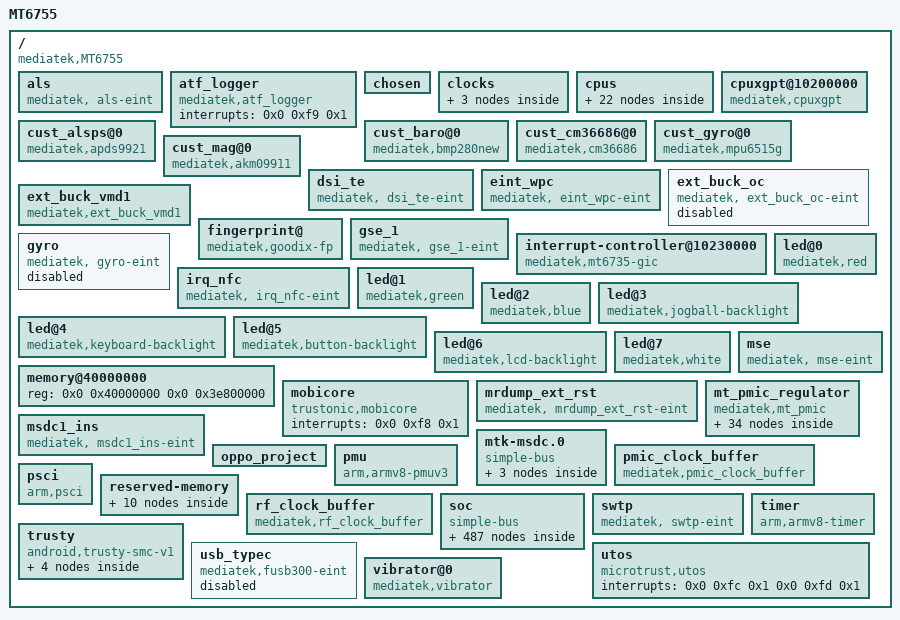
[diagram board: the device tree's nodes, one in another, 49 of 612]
/dts-v1/;

/ {
	#address-cells = <0x2>;
	#size-cells = <0x2>;
	compatible = "mediatek,MT6755";
	interrupt-parent = <0x1>;
	model = "MT6755";

	als {
		compatible = "mediatek, als-eint";
		debounce = <0x6 0x0>;
		interrupt-parent = <0x1c>;
		interrupts = <0x6 0x2>;
		status = "okay";
	};

	atf_logger {
		compatible = "mediatek,atf_logger";
		interrupts = <0x0 0xf9 0x1>;
	};

	chosen {
		atag,videolfb-fb_base_h = <0x0>;
		atag,videolfb-fb_base_l = <0x7e800000>;
		atag,videolfb-fps = <0x1770>;
		atag,videolfb-islcm_inited = <0x0>;
		atag,videolfb-islcmfound = <0x1>;
		atag,videolfb-lcmname = "nt35695_fhd_dsi_cmd_truly_nt50358_drv";
		atag,videolfb-vramSize = <0x1800000>;
		bootargs = "console=tty0 console=ttyMT0,921600n1 root=/dev/ram initrd=0x44000000,0x4B434E loglevel=8";
	};

	clocks {

		clk26m {
			#clock-cells = <0x0>;
			clock-frequency = <0x18cba80>;
			compatible = "fixed-clock";
			linux,phandle = <0x41>;
			phandle = <0x41>;
		};

		clk32k {
			#clock-cells = <0x0>;
			clock-frequency = <0x7d00>;
			compatible = "fixed-clock";
			linux,phandle = <0x21>;
			phandle = <0x21>;
		};

		clk_null {
			#clock-cells = <0x0>;
			clock-frequency = <0x0>;
			compatible = "fixed-clock";
		};
	};

	cpus {
		#address-cells = <0x1>;
		#size-cells = <0x0>;

		cpu-map {

			cluster0 {

				core0 {
					cpu = <0x14>;
				};

				core1 {
					cpu = <0x15>;
				};

				core2 {
					cpu = <0x16>;
				};

				core3 {
					cpu = <0x17>;
				};
			};

			cluster1 {

				core0 {
					cpu = <0x18>;
				};

				core1 {
					cpu = <0x19>;
				};

				core2 {
					cpu = <0x1a>;
				};

				core3 {
					cpu = <0x1b>;
				};
			};
		};

		cpu@000 {
			clock-frequency = <0x44300e00>;
			compatible = "arm,cortex-a53";
			cpu-idle-states = <0x12 0x12 0x12 0x13 0x13 0x13>;
			cpu-release-addr = <0x0 0x40000200>;
			device_type = "cpu";
			enable-method = "mt-boot";
			linux,phandle = <0x14>;
			phandle = <0x14>;
			reg = <0x0>;
		};

		cpu@001 {
			clock-frequency = <0x44300e00>;
			compatible = "arm,cortex-a53";
			cpu-idle-states = <0x12 0x12 0x12 0x13 0x13 0x13>;
			cpu-release-addr = <0x0 0x40000200>;
			device_type = "cpu";
			enable-method = "mt-boot";
			linux,phandle = <0x15>;
			phandle = <0x15>;
			reg = <0x1>;
		};

		cpu@002 {
			clock-frequency = <0x44300e00>;
			compatible = "arm,cortex-a53";
			cpu-idle-states = <0x12 0x12 0x12 0x13 0x13 0x13>;
			cpu-release-addr = <0x0 0x40000200>;
			device_type = "cpu";
			enable-method = "mt-boot";
			linux,phandle = <0x16>;
			phandle = <0x16>;
			reg = <0x2>;
		};

		cpu@003 {
			clock-frequency = <0x44300e00>;
			compatible = "arm,cortex-a53";
			cpu-idle-states = <0x12 0x12 0x12 0x13 0x13 0x13>;
			cpu-release-addr = <0x0 0x40000200>;
			device_type = "cpu";
			enable-method = "mt-boot";
			linux,phandle = <0x17>;
			phandle = <0x17>;
			reg = <0x3>;
		};

		cpu@100 {
			clock-frequency = <0x743aa380>;
			compatible = "arm,cortex-a53";
			cpu-idle-states = <0x12 0x12 0x12 0x13 0x13 0x13>;
			cpu-release-addr = <0x0 0x40000200>;
			device_type = "cpu";
			enable-method = "mt-boot";
			linux,phandle = <0x18>;
			phandle = <0x18>;
			reg = <0x100>;
		};

		cpu@101 {
			clock-frequency = <0x743aa380>;
			compatible = "arm,cortex-a53";
			cpu-idle-states = <0x12 0x12 0x12 0x13 0x13 0x13>;
			cpu-release-addr = <0x0 0x40000200>;
			device_type = "cpu";
			enable-method = "mt-boot";
			linux,phandle = <0x19>;
			phandle = <0x19>;
			reg = <0x101>;
		};

		cpu@102 {
			clock-frequency = <0x743aa380>;
			compatible = "arm,cortex-a53";
			cpu-idle-states = <0x12 0x12 0x12 0x13 0x13 0x13>;
			cpu-release-addr = <0x0 0x40000200>;
			device_type = "cpu";
			enable-method = "mt-boot";
			linux,phandle = <0x1a>;
			phandle = <0x1a>;
			reg = <0x102>;
		};

		cpu@103 {
			clock-frequency = <0x743aa380>;
			compatible = "arm,cortex-a53";
			cpu-idle-states = <0x12 0x12 0x12 0x13 0x13 0x13>;
			cpu-release-addr = <0x0 0x40000200>;
			device_type = "cpu";
			enable-method = "mt-boot";
			linux,phandle = <0x1b>;
			phandle = <0x1b>;
			reg = <0x103>;
		};

		idle-states {
			entry-method = "arm,psci";

			cluster-sleep-0 {
				arm,psci-suspend-param = <0x1010000>;
				compatible = "arm,idle-state";
				entry-latency-us = <0x320>;
				exit-latency-us = <0x3e8>;
				linux,phandle = <0x12>;
				min-residency-us = <0x7d0>;
				phandle = <0x12>;
			};

			cpu-sleep-0-0 {
				arm,psci-suspend-param = <0x10000>;
				compatible = "arm,idle-state";
				entry-latency-us = <0x258>;
				exit-latency-us = <0x258>;
				linux,phandle = <0x13>;
				min-residency-us = <0x4b0>;
				phandle = <0x13>;
			};
		};
	};

	cpuxgpt@10200000 {
		compatible = "mediatek,cpuxgpt";
		interrupts = <0x0 0x40 0x4 0x0 0x41 0x4 0x0 0x42 0x4 0x0 0x43 0x4 0x0 0x44 0x4 0x0 0x45 0x4 0x0 0x46 0x4 0x0 0x47 0x4>;
		reg = <0x0 0x10200000 0x0 0x1000>;
	};

	cust_alsps@0 {
		als_gain1 = <0x2>;
		als_gain2 = <0x3>;
		als_level = <0x0 0x101 0x27d 0x403 0x8f9 0x15d4 0x1a4a 0x2c25 0x4fe1 0x64a8 0x7992 0xb1f0 0xe251 0xe251 0xe251>;
		als_value = <0x0 0x84 0x130 0x1f6 0x3ec 0x7d3 0xbbe 0x138e 0x1f44 0x2710 0x2ee0 0x3e80 0x4e20 0x4e20 0x4e20 0x4e20>;
		compatible = "mediatek,apds9921";
		eint_gpio = <0x6>;
		i2c_addr = <0x53 0x0 0x0 0x0>;
		i2c_num = <0x1>;
		is_batch_supported_als = <0x1>;
		is_batch_supported_ps = <0x1>;
		polling_mode_als = <0x1>;
		polling_mode_ps = <0x0>;
		power_id = <0xffff>;
		power_vol = <0x0>;
		ps_threshold_high = <0x190>;
		ps_threshold_low = <0x15e>;
		sec_para_supported = <0x1>;
	};

	cust_baro@0 {
		compatible = "mediatek,bmp280new";
		direction = <0x0>;
		firlen = <0x20>;
		i2c_num = <0x1>;
		is_batch_supported = <0x0>;
		power_id = <0xffff>;
		power_vol = <0x0>;
	};

	cust_cm36686@0 {
		als_gain1 = <0x2>;
		als_gain2 = <0x3>;
		als_level = <0x0 0x101 0x27d 0x403 0x8f9 0x15d4 0x1a4a 0x2c25 0x4fe1 0x64a8 0x7992 0xb1f0 0xe251 0xe251 0xe251>;
		als_value = <0x0 0x84 0x130 0x1f6 0x3ec 0x7d3 0xbbe 0x138e 0x1f44 0x2710 0x2ee0 0x3e80 0x4e20 0x4e20 0x4e20 0x4e20>;
		compatible = "mediatek,cm36686";
		eint_gpio = <0x6>;
		i2c_addr = <0x60 0x0 0x0 0x0>;
		i2c_num = <0x1>;
		is_batch_supported_als = <0x1>;
		is_batch_supported_ps = <0x1>;
		polling_mode_als = <0x1>;
		polling_mode_ps = <0x0>;
		power_id = <0xffff>;
		power_vol = <0x0>;
		ps_threshold_high = <0x190>;
		ps_threshold_low = <0x15e>;
		sec_para_supported = <0x1>;
	};

	cust_gyro@0 {
		compatible = "mediatek,mpu6515g";
		direction = <0x6>;
		firlen = <0x0>;
		i2c_num = <0x1>;
		is_batch_supported = <0x0>;
		power_id = <0xffff>;
		power_vol = <0x0>;
	};

	cust_mag@0 {
		compatible = "mediatek,akm09911";
		direction = <0x3>;
		i2c_addr = <0xc 0x0 0x0 0x0>;
		i2c_num = <0x1>;
		power_id = <0xffff>;
		power_vol = <0x0>;
	};

	dsi_te {
		compatible = "mediatek, dsi_te-eint";
		debounce = <0x2c 0x0>;
		interrupt-parent = <0x1c>;
		interrupts = <0x2c 0x1>;
		status = "okay";
	};

	eint_wpc {
		compatible = "mediatek, eint_wpc-eint";
		debounce = <0x2a 0x0>;
		interrupt-parent = <0x1c>;
		interrupts = <0x2a 0x1>;
		status = "okay";
	};

	ext_buck_oc {
		compatible = "mediatek, ext_buck_oc-eint";
		status = "disabled";
	};

	ext_buck_vmd1 {
		compatible = "mediatek,ext_buck_vmd1";
		pinctrl-0 = <0x8e>;
		pinctrl-1 = <0x8f>;
		pinctrl-2 = <0x90>;
		pinctrl-names = "default", "vmd1_sel_low", "vmd1_sel_high";
	};

	fingerprint@ {
		compatible = "mediatek,goodix-fp";
	};

	gse_1 {
		compatible = "mediatek, gse_1-eint";
		debounce = <0x4 0x0>;
		interrupt-parent = <0x1c>;
		interrupts = <0x4 0x2>;
		status = "okay";
	};

	gyro {
		compatible = "mediatek, gyro-eint";
		status = "disabled";
	};

	interrupt-controller@10230000 {
		#address-cells = <0x0>;
		#interrupt-cells = <0x3>;
		compatible = "mediatek,mt6735-gic";
		interrupt-controller;
		linux,phandle = <0x1>;
		phandle = <0x1>;
		reg = <0x0 0x10231000 0x0 0x1000 0x0 0x10232000 0x0 0x1000 0x0 0x10200620 0x0 0x1000>;
	};

	irq_nfc {
		compatible = "mediatek, irq_nfc-eint";
		debounce = <0x1a 0x0>;
		interrupt-parent = <0x1c>;
		interrupts = <0x1a 0x4>;
		status = "okay";
	};

	led@0 {
		compatible = "mediatek,red";
		data = <0x1>;
		led_mode = <0x0>;
		pwm_config = <0x0 0x0 0x0 0x0 0x0>;
	};

	led@1 {
		compatible = "mediatek,green";
		data = <0x1>;
		led_mode = <0x0>;
		pwm_config = <0x0 0x0 0x0 0x0 0x0>;
	};

	led@2 {
		compatible = "mediatek,blue";
		data = <0x1>;
		led_mode = <0x0>;
		pwm_config = <0x0 0x0 0x0 0x0 0x0>;
	};

	led@3 {
		compatible = "mediatek,jogball-backlight";
		data = <0x1>;
		led_mode = <0x0>;
		pwm_config = <0x0 0x0 0x0 0x0 0x0>;
	};

	led@4 {
		compatible = "mediatek,keyboard-backlight";
		data = <0x1>;
		led_mode = <0x0>;
		pwm_config = <0x0 0x0 0x0 0x0 0x0>;
	};

	led@5 {
		compatible = "mediatek,button-backlight";
		data = <0x1>;
		led_mode = <0x0>;
		pwm_config = <0x0 0x0 0x0 0x0 0x0>;
	};

	led@6 {
		compatible = "mediatek,lcd-backlight";
		data = <0x1>;
		led_mode = <0x4>;
		pwm_config = <0x0 0x0 0x0 0x0 0x0>;
	};

	led@7 {
		compatible = "mediatek,white";
		data = <0x1>;
		led_mode = <0x3>;
		pwm_config = <0x0 0x0 0x0 0x0 0x0>;
	};

	memory@40000000 {
		device_type = "memory";
		reg = <0x0 0x40000000 0x0 0x3e800000>;
	};

	mobicore {
		compatible = "trustonic,mobicore";
		interrupts = <0x0 0xf8 0x1>;
	};

	mrdump_ext_rst {
		compatible = "mediatek, mrdump_ext_rst-eint";
		debounce = <0x7 0x7d000>;
		interrupt-parent = <0x1c>;
		interrupts = <0x7 0x8>;
		status = "okay";
	};

	msdc1_ins {
		compatible = "mediatek, msdc1_ins-eint";
		debounce = <0x3 0x3e8>;
		interrupt-parent = <0x1c>;
		interrupts = <0x3 0x8>;
		status = "okay";
	};

	mse {
		compatible = "mediatek, mse-eint";
		debounce = <0x5 0x0>;
		interrupt-parent = <0x1c>;
		interrupts = <0x5 0x4>;
		status = "okay";
	};

	mt_pmic_regulator {
		compatible = "mediatek,mt_pmic";

		buck_regulators {
			compatible = "mediatek,mt_pmic_buck_regulators";

			buck_vcore {
				regulator-boot-on;
				regulator-enable-ramp-delay = <0x1e>;
				regulator-max-microvolt = <0x154456>;
				regulator-min-microvolt = <0x927c0>;
				regulator-name = "vcore";
				regulator-ramp-delay = <0x186a>;
			};

			buck_vcore2 {
				regulator-boot-on;
				regulator-enable-ramp-delay = <0x1e>;
				regulator-max-microvolt = <0x154456>;
				regulator-min-microvolt = <0x927c0>;
				regulator-name = "vcore2";
				regulator-ramp-delay = <0x186a>;
			};

			buck_vproc {
				regulator-always-on;
				regulator-boot-on;
				regulator-enable-ramp-delay = <0x1e>;
				regulator-max-microvolt = <0x154456>;
				regulator-min-microvolt = <0x927c0>;
				regulator-name = "vproc";
				regulator-ramp-delay = <0x186a>;
			};

			buck_vs1 {
				regulator-always-on;
				regulator-boot-on;
				regulator-enable-ramp-delay = <0x1e>;
				regulator-max-microvolt = <0x154456>;
				regulator-min-microvolt = <0x927c0>;
				regulator-name = "vs1";
				regulator-ramp-delay = <0x186a>;
			};
		};

		ldo_regulators {
			compatible = "mediatek,mt_pmic_ldo_regulators";

			ldo_vaud28 {
				regulator-boot-on;
				regulator-enable-ramp-delay = <0xf0>;
				regulator-max-microvolt = <0x2ab980>;
				regulator-min-microvolt = <0x1b7740>;
				regulator-name = "vaud28";
			};

			ldo_vaux18 {
				regulator-boot-on;
				regulator-enable-ramp-delay = <0xf0>;
				regulator-max-microvolt = <0x2ab980>;
				regulator-min-microvolt = <0x1b7740>;
				regulator-name = "vaux18";
			};

			ldo_vcama {
				linux,phandle = <0x51>;
				phandle = <0x51>;
				regulator-default-on = <0x0>;
				regulator-enable-ramp-delay = <0xf0>;
				regulator-max-microvolt = <0x2ab980>;
				regulator-min-microvolt = <0x16e360>;
				regulator-name = "vcama";
				status = "okay";
			};

			ldo_vcamd {
				linux,phandle = <0x52>;
				phandle = <0x52>;
				regulator-default-on = <0x0>;
				regulator-enable-ramp-delay = <0xf0>;
				regulator-max-microvolt = <0x1b7740>;
				regulator-min-microvolt = <0xdbba0>;
				regulator-name = "vcamd";
				status = "okay";
			};

			ldo_vcamio {
				linux,phandle = <0x53>;
				phandle = <0x53>;
				regulator-default-on = <0x0>;
				regulator-enable-ramp-delay = <0xf0>;
				regulator-max-microvolt = <0x1b7740>;
				regulator-min-microvolt = <0x124f80>;
				regulator-name = "vcamio";
				status = "okay";
			};

			ldo_vcn18 {
				regulator-enable-ramp-delay = <0xf0>;
				regulator-max-microvolt = <0x1b7740>;
				regulator-min-microvolt = <0x1b7740>;
				regulator-name = "vcn18";
			};

			ldo_vcn28 {
				regulator-enable-ramp-delay = <0xf0>;
				regulator-max-microvolt = <0x2ab980>;
				regulator-min-microvolt = <0x1b7740>;
				regulator-name = "vcn28";
			};

			ldo_vcn33_bt {
				regulator-enable-ramp-delay = <0xf0>;
				regulator-max-microvolt = <0x36ee80>;
				regulator-min-microvolt = <0x325aa0>;
				regulator-name = "vcn33_bt";
			};

			ldo_vcn33_wifi {
				regulator-enable-ramp-delay = <0xf0>;
				regulator-max-microvolt = <0x36ee80>;
				regulator-min-microvolt = <0x325aa0>;
				regulator-name = "vcn33_wifi";
			};

			ldo_vdram {
				linux,phandle = <0x9c>;
				phandle = <0x9c>;
				regulator-boot-on;
				regulator-enable-ramp-delay = <0xf0>;
				regulator-max-microvolt = <0x177fa0>;
				regulator-min-microvolt = <0x12ebc0>;
				regulator-name = "vdram";
			};

			ldo_vemc {
				linux,phandle = <0x5>;
				phandle = <0x5>;
				regulator-boot-on;
				regulator-enable-ramp-delay = <0xf0>;
				regulator-max-microvolt = <0x325aa0>;
				regulator-min-microvolt = <0x2c4020>;
				regulator-name = "vemc";
			};

			ldo_vibr {
				linux,phandle = <0x96>;
				phandle = <0x96>;
				regulator-default-on = <0x0>;
				regulator-enable-ramp-delay = <0x28>;
				regulator-max-microvolt = <0x325aa0>;
				regulator-min-microvolt = <0x124f80>;
				regulator-name = "vibr";
				status = "okay";
			};

			ldo_vio18 {
				linux,phandle = <0x98>;
				phandle = <0x98>;
				regulator-boot-on;
				regulator-enable-ramp-delay = <0xf0>;
				regulator-max-microvolt = <0x1b7740>;
				regulator-min-microvolt = <0x1b7740>;
				regulator-name = "vio18";
			};

			ldo_vio28 {
				linux,phandle = <0x95>;
				phandle = <0x95>;
				regulator-boot-on;
				regulator-enable-ramp-delay = <0xf0>;
				regulator-max-microvolt = <0x2ab980>;
				regulator-min-microvolt = <0x2ab980>;
				regulator-name = "vio28";
			};

			ldo_vldo28 {
				linux,phandle = <0x54>;
				phandle = <0x54>;
				regulator-default-on = <0x0>;
				regulator-enable-ramp-delay = <0xf0>;
				regulator-max-microvolt = <0x325aa0>;
				regulator-min-microvolt = <0x124f80>;
				regulator-name = "vldo28";
				status = "okay";
			};

			ldo_vldo28_1 {
				regulator-enable-ramp-delay = <0xf0>;
				regulator-max-microvolt = <0x325aa0>;
				regulator-min-microvolt = <0x124f80>;
				regulator-name = "vldo28_1";
			};

			ldo_vmc {
				linux,phandle = <0xd>;
				phandle = <0xd>;
				regulator-enable-ramp-delay = <0xf0>;
				regulator-max-microvolt = <0x325aa0>;
				regulator-min-microvolt = <0x124f80>;
				regulator-name = "vmc";
			};

			ldo_vmch {
				linux,phandle = <0xc>;
				phandle = <0xc>;
				regulator-enable-ramp-delay = <0x28>;
				regulator-max-microvolt = <0x325aa0>;
				regulator-min-microvolt = <0x2c4020>;
				regulator-name = "vmch";
			};

			ldo_vrf12 {
				linux,phandle = <0x9b>;
				phandle = <0x9b>;
				regulator-enable-ramp-delay = <0xc8>;
				regulator-max-microvolt = <0x1b7740>;
				regulator-min-microvolt = <0xdbba0>;
				regulator-name = "vrf12";
			};

			ldo_vrf18 {
				linux,phandle = <0x97>;
				phandle = <0x97>;
				regulator-enable-ramp-delay = <0xc8>;
				regulator-max-microvolt = <0x1b7740>;
				regulator-min-microvolt = <0x1b7740>;
				regulator-name = "vrf18";
			};

			ldo_vsim1 {
				linux,phandle = <0x93>;
				phandle = <0x93>;
				regulator-default-on = <0x0>;
				regulator-enable-ramp-delay = <0xf0>;
				regulator-max-microvolt = <0x2f4d60>;
				regulator-min-microvolt = <0x19f0a0>;
				regulator-name = "vsim1";
				status = "okay";
			};

			ldo_vsim2 {
				linux,phandle = <0x94>;
				phandle = <0x94>;
				regulator-default-on = <0x0>;
				regulator-enable-ramp-delay = <0xf0>;
				regulator-max-microvolt = <0x2f4d60>;
				regulator-min-microvolt = <0x19f0a0>;
				regulator-name = "vsim2";
				status = "okay";
			};

			ldo_vsram_proc {
				linux,phandle = <0x99>;
				phandle = <0x99>;
				regulator-boot-on;
				regulator-enable-ramp-delay = <0xc8>;
				regulator-max-microvolt = <0x154456>;
				regulator-min-microvolt = <0x927c0>;
				regulator-name = "vsram_proc";
				regulator-ramp-delay = <0x186a>;
			};

			ldo_vtcxo24 {
				linux,phandle = <0x91>;
				phandle = <0x91>;
				regulator-boot-on;
				regulator-enable-ramp-delay = <0x64>;
				regulator-max-microvolt = <0x2ab980>;
				regulator-min-microvolt = <0x1b7740>;
				regulator-name = "vtcxo24";
			};

			ldo_vtcxo28 {
				linux,phandle = <0x92>;
				phandle = <0x92>;
				regulator-enable-ramp-delay = <0x64>;
				regulator-max-microvolt = <0x2ab980>;
				regulator-min-microvolt = <0x1b7740>;
				regulator-name = "vtcxo28";
			};

			ldo_vusb33 {
				regulator-boot-on;
				regulator-enable-ramp-delay = <0xf0>;
				regulator-max-microvolt = <0x325aa0>;
				regulator-min-microvolt = <0x325aa0>;
				regulator-name = "vusb33";
			};

			ldo_vxo22 {
				linux,phandle = <0x9a>;
				phandle = <0x9a>;
				regulator-boot-on;
				regulator-enable-ramp-delay = <0x64>;
				regulator-max-microvolt = <0x2ab980>;
				regulator-min-microvolt = <0x1b7740>;
				regulator-name = "vxo22";
			};
		};

		regulators_supply {
			compatible = "mediatek,mt_pmic_regulator_supply";
			vdram-supply = <0x9c>;
			vemc-supply = <0x5>;
			vibr-supply = <0x96>;
			vio18-supply = <0x98>;
			vio28-supply = <0x95>;
			vmc-supply = <0xd>;
			vmch-supply = <0xc>;
			vrf12-supply = <0x9b>;
			vrf18-supply = <0x97>;
			vsim1-supply = <0x93>;
			vsim2-supply = <0x94>;
			vsram_proc-supply = <0x99>;
			vtcxo24-supply = <0x91>;
			vtcxo28-supply = <0x92>;
			vxo22-supply = <0x9a>;
		};
	};

	mtk-msdc.0 {
		#address-cells = <0x1>;
		#size-cells = <0x1>;
		compatible = "simple-bus";
		ranges = <0x0 0x0 0x0 0xffffffff>;

		msdc0@11230000 {
			bootable;
			bus-width = <0x8>;
			cap-mmc-highspeed;
			clk_src = [01];
			clock-names = "MSDC0-CLOCK";
			clocks = <0x2 0x1e>;
			compatible = "mediatek,mt6755-mmc";
			host_function = [00];
			interrupts = <0x0 0x4f 0x8>;
			max-frequency = <0xbebc200>;
			mmc-hs200-1_8v;
			mmc-hs400-1_8v;
			msdc-sys-suspend;
			non-removable;
			pinctl = <0x3>;
			reg = <0x11230000 0x10000>;
			register_setting = <0x4>;
			status = "okay";
			vmmc-supply = <0x5>;
		};

		msdc1@11240000 {
			bus-width = <0x4>;
			cap-sd-highspeed;
			cd-gpios = <0xb 0x3 0x0>;
			cd_level = [01];
			clk_src = [07];
			clock-names = "MSDC1-CLOCK";
			clocks = <0x2 0x20>;
			compatible = "mediatek,mt6755-mmc";
			host_function = [01];
			interrupts = <0x0 0x50 0x8>;
			max-frequency = <0xbebc200>;
			msdc-sys-suspend;
			pinctl = <0x6>;
			pinctl_ddr50 = <0x9>;
			pinctl_sdr104 = <0x7>;
			pinctl_sdr50 = <0x8>;
			pinctrl-0 = <0xe>;
			pinctrl-1 = <0xf>;
			pinctrl-names = "msdc1_on", "msdc1_off";
			reg = <0x11240000 0x10000>;
			register_setting = <0xa>;
			sd-uhs-sdr104;
			sd-uhs-sdr12;
			sd-uhs-sdr25;
			sd-uhs-sdr50;
			status = "okay";
			vmmc-supply = <0xc>;
			vqmmc-supply = <0xd>;
		};

		msdc2@11250000 {
			bus-width = <0x4>;
			cap-sd-highspeed;
			clk_src = [07];
			clock-names = "MSDC2-CLOCK";
			clocks = <0x2 0x21>;
			compatible = "mediatek,mt6755-mmc";
			host_function = [02];
			interrupts = <0x0 0x51 0x8>;
			keep-power-in-suspend;
			max-frequency = <0xbebc200>;
			non-removable;
			pinctl = <0x10>;
			reg = <0x11250000 0x10000>;
			register_setting = <0x11>;
			sd-uhs-ddr50;
			sd-uhs-sdr104;
			sd-uhs-sdr12;
			sd-uhs-sdr25;
			sd-uhs-sdr50;
			status = "disable";
		};
	};

	oppo_project {
		nModem = <0x0>;
		nOperator = <0x0>;
		nPCBVersion = <0x0>;
		nProject = <0x0>;
	};

	pmic_clock_buffer {
		compatible = "mediatek,pmic_clock_buffer";
		mediatek,clkbuf-config = <0x2 0x1 0x1 0x2>;
		mediatek,clkbuf-driving-current = <0x2 0x2 0x2 0x2>;
		mediatek,clkbuf-quantity = <0x4>;
		status = "okay";
	};

	pmu {
		compatible = "arm,armv8-pmuv3";
		interrupts = <0x0 0x8 0x8 0x0 0x9 0x8 0x0 0xa 0x8 0x0 0xb 0x8 0x0 0xc 0x8 0x0 0xd 0x8 0x0 0xe 0x8 0x0 0xf 0x8>;
	};

	psci {
		affinity_info = <0x84000004>;
		compatible = "arm,psci";
		cpu_off = <0x84000002>;
		cpu_on = <0x84000003>;
		cpu_suspend = <0x84000001>;
		method = "smc";
	};

	reserved-memory {
		#address-cells = <0x2>;
		#size-cells = <0x2>;
		ranges;

		atf-reserved-memory@44600000 {
			compatible = "mediatek,mt6755-atf-reserved-memory";
			no-map;
			reg = <0x0 0x44600000 0x0 0x40000>;
		};

		consys-reserve-memory {
			alignment = <0x0 0x200000>;
			alloc-ranges = <0x0 0x40000000 0x0 0x60000000>;
			compatible = "mediatek,consys-reserve-memory";
			no-map;
			size = <0x0 0x100000>;
		};

		lk-reserved-memory@46000000 {
			compatible = "mediatek,lk";
			reg = <0x0 0x46000000 0x0 0x400000>;
		};

		minirdump-reserved-memory@444f0000 {
			compatible = "mediatek, minirdump";
			reg = <0x0 0x444f0000 0x0 0x10000>;
		};

		preloader-reserved-memory@44800000 {
			compatible = "mediatek,preloader";
			reg = <0x0 0x44800000 0x0 0x100000>;
		};

		pstore-reserved-memory@44410000 {
			compatible = "mediatek,pstore";
			reg = <0x0 0x44410000 0x0 0xe0000>;
		};

		ram_console-reserved-memory@44400000 {
			compatible = "mediatek,ram_console";
			reg = <0x0 0x44400000 0x0 0x10000>;
		};

		reserve-memory-ccci_md1 {
			alignment = <0x0 0x2000000>;
			alloc-ranges = <0x0 0x40000000 0x0 0xc0000000>;
			compatible = "mediatek,reserve-memory-ccci_md1";
			no-map;
			size = <0x0 0xa100000>;
		};

		reserve-memory-ccci_share {
			alignment = <0x0 0x4000000>;
			alloc-ranges = <0x0 0x40000000 0x0 0xc0000000>;
			compatible = "mediatek,reserve-memory-ccci_share";
			no-map;
			size = <0x0 0x600000>;
		};

		spm-reserve-memory {
			alignment = <0x0 0x10000>;
			alloc-ranges = <0x0 0x40000000 0x0 0x60000000>;
			compatible = "mediatek,spm-reserve-memory";
			no-map;
			size = <0x0 0xe000>;
		};
	};

	rf_clock_buffer {
		compatible = "mediatek,rf_clock_buffer";
		mediatek,clkbuf-config = <0x2 0x0 0x1 0x1>;
		mediatek,clkbuf-driving-current = <0x2 0x2 0x2 0x2>;
		mediatek,clkbuf-quantity = <0x4>;
		status = "okay";
	};

	soc {
		#address-cells = <0x1>;
		#size-cells = <0x1>;
		compatible = "simple-bus";
		ranges;

		accdet@ {
			accdet-mic-mode = <0x1>;
			accdet-mic-vol = <0x7>;
			accdet-plugout-debounce = <0x14>;
			compatible = "mediatek,mt6755-accdet";
			debounce = <0x2 0x3e800>;
			headset-four-key-threshold = <0x0 0x3a 0x79 0xc0 0x1c2>;
			headset-mode-setting = <0x500 0x500 0x1 0x3f0 0x800 0x800 0x200>;
			headset-three-key-threshold = <0x0 0x50 0xdc 0x1f4>;
			interrupt-parent = <0x1c>;
			interrupts = <0x2 0x8>;
			pinctrl-0 = <0x6c>;
			pinctrl-1 = <0x6d>;
			pinctrl-names = "default", "state_eint_as_int";
			status = "okay";
		};

		adc_hw@11001000 {
			clock-names = "auxadc-main";
			clocks = <0x2 0x26>;
			compatible = "mediatek,mt6755-auxadc";
			interrupts = <0x0 0x4a 0x2>;
			reg = <0x11001000 0x1000>;

			adc_channel@ {
				compatible = "mediatek,adc_channel";
				mediatek,adc_fdd_rf_params_dynamic_custom_ch = <0xc>;
				mediatek,temperature0 = <0x0>;
				mediatek,temperature1 = <0x1>;
				status = "okay";
			};
		};

		aes_top0@10016000 {
			compatible = "mediatek,aes_top0";
			reg = <0x10016000 0x1000>;
		};

		aes_top1@10017000 {
			compatible = "mediatek,aes_top1";
			reg = <0x10017000 0x1000>;
		};

		als_ps@0 {
			compatible = "mediatek,als_ps";
			pinctrl-0 = <0x74>;
			pinctrl-1 = <0x75>;
			pinctrl-names = "pin_default", "pin_cfg";
			status = "okay";
		};

		ap2c2k_ccif@1020b000 {
			ccif,capability = <0x2>;
			ccif,major = <0xa9>;
			ccif,minor_base = <0x0>;
			cell-index = <0x2>;
			clock-names = "scp-sys-md2-main";
			clocks = <0x24 0x2>;
			compatible = "mediatek,ap2c2k_ccif";
			interrupts = <0x0 0x8d 0x8 0x0 0xdc 0x2>;
			mediatek,md_smem_size = <0x400000>;
			reg = <0x1020b000 0x1000 0x10211000 0x300 0x10213000 0x300>;
		};

		ap_ccif0@10209000 {
			compatible = "mediatek,ap_ccif0";
			interrupts = <0x0 0x8b 0x8>;
			reg = <0x10209000 0x1000>;
		};

		ap_ccif1@1020b000 {
			compatible = "mediatek,ap_ccif1";
			interrupts = <0x0 0x8d 0x8>;
			reg = <0x1020b000 0x1000>;
		};

		ap_dma@11000000 {
			compatible = "mediatek,ap_dma";
			interrupts = <0x0 0x61 0x8>;
			reg = <0x11000000 0x1000>;
		};

		apmixedsys@1000c000 {
			#clock-cells = <0x1>;
			compatible = "mediatek,mt6755-apmixedsys", "mediatek,apmixed";
			linux,phandle = <0x40>;
			phandle = <0x40>;
			reg = <0x1000c000 0x1000 0x10006000 0x1000>;
		};

		apuart0@11002000 {
			cell-index = <0x0>;
			clock-div = <0x1>;
			clock-frequency = <0x18cba80>;
			clock-names = "uart0-main", "uart-apdma";
			clocks = <0x2 0x14 0x2 0x2a>;
			compatible = "mediatek,mt6755-uart";
			interrupts = <0x0 0x5b 0x8 0x0 0x67 0x8 0x0 0x68 0x8>;
			pinctrl-0 = <0x29>;
			pinctrl-1 = <0x2a>;
			pinctrl-2 = <0x2b>;
			pinctrl-3 = <0x2c>;
			pinctrl-4 = <0x2d>;
			pinctrl-names = "uart0_gpio_default", "uart0_rx_set", "uart0_rx_clear", "uart0_tx_set", "uart0_tx_clear";
			reg = <0x11002000 0x1000 0x11000380 0x1000 0x11000400 0x80>;
			status = "okay";
		};

		apuart1@11003000 {
			cell-index = <0x1>;
			clock-div = <0x1>;
			clock-frequency = <0x18cba80>;
			clock-names = "uart1-main";
			clocks = <0x2 0x15>;
			compatible = "mediatek,mt6755-uart";
			interrupts = <0x0 0x5c 0x8 0x0 0x69 0x8 0x0 0x6a 0x8>;
			reg = <0x11003000 0x1000 0x11000480 0x80 0x11000500 0x80>;
		};

		apxgpt@10008000 {
			clocks = <0x20 0x3c 0x21>;
			compatible = "mediatek,mt6755-timer", "mediatek,mt6577-timer";
			interrupts = <0x0 0x9a 0x8>;
			reg = <0x10008000 0x1000>;
		};

		audiosys@11220000 {
			#clock-cells = <0x1>;
			compatible = "mediatek,mt6755-audiosys";
			linux,phandle = <0x3f>;
			phandle = <0x3f>;
			reg = <0x11220000 0x10000>;
		};

		barometer@0 {
			compatible = "mediatek,barometer";
		};

		bat_metter {
			ac_charger_current = <0x13880>;
			aging1_load_soc = <0x46>;
			aging1_update_soc = <0x1e>;
			aging_tuning_value = <0x67>;
			apple_0_5a_charger_current = <0xc350>;
			apple_1_0a_charger_current = <0xfde8>;
			apple_2_1a_charger_current = <0x13880>;
			bat_low_temp_protect_enable = <0x0>;
			batt_temperature_table = <0xffffffec 0x10a8d 0xfffffff1 0xd192 0xfffffff6 0xa60a 0xfffffffb 0x8464 0x0 0x6a53 0x5 0x5605 0xa 0x4606 0xf 0x3952 0x14 0x2f31 0x19 0x2710 0x1e 0x207b 0x23 0x1b24 0x28 0x16ca 0x2d 0x1335 0x32 0x1041 0x37 0xdcf 0x3c 0xbc6>;
			batt_temperature_table_num = <0x11>;
			battery_profile_t0 = <0x0 0x10cf 0x6 0x10b9 0xd 0x10a5 0x12 0x1090 0x19 0x1079 0x1f 0x1062 0x26 0x1049 0x2c 0x1031 0x33 0x1015 0x38 0xff8 0x3e 0xfe4 0x45 0xfcf 0x4b 0xfb3 0x52 0xf9d 0x57 0xf8d 0x5e 0xf7f 0x64 0xf74 0x6b 0xf66 0x71 0xf59 0x76 0xf49 0x7d 0xf37 0x80 0xf28 0x87 0xf1d 0x8d 0xf11 0x93 0xf08 0x9a 0xeff 0x9f 0xef6 0xa6 0xeef 0xac 0xeea 0xb3 0xee3 0xb9 0xede 0xc0 0xed8 0xc5 0xed4 0xcb 0xecf 0xd2 0xecb 0xd8 0xec5 0xdf 0xebf 0xe4 0xeba 0xeb 0xeb0 0xf1 0xea8 0xf8 0xe9e 0xfe 0xe93 0x103 0xe89 0x10a 0xe81 0x110 0xe78 0x117 0xe72 0x11d 0xe68 0x124 0xe51 0x129 0xe1d 0x130 0xdc6 0x133 0xd8a 0x136 0xd74 0x139 0xd60 0x139 0xd4c>;
			battery_profile_t0_num = <0x52>;
			battery_profile_t1 = <0x0 0x10dc 0x7 0x10bb 0xc 0x1094 0x14 0x1072 0x16 0x1059 0x1d 0x1044 0x22 0x1030 0x29 0x1020 0x31 0x100d 0x36 0xffd 0x3d 0xff0 0x3f 0xfe5 0x47 0xfcf 0x4e 0xfb7 0x53 0xfa3 0x5a 0xf95 0x5f 0xf89 0x64 0xf7f 0x69 0xf73 0x70 0xf64 0x78 0xf53 0x7c 0xf43 0x84 0xf33 0x8b 0xf25 0x8d 0xf18 0x95 0xf0f 0x9a 0xf06 0xa1 0xefd 0xa6 0xef7 0xad 0xeef 0xb5 0xee7 0xb7 0xee3 0xbe 0xedc 0xc3 0xed7 0xca 0xed2 0xd2 0xece 0xd7 0xec9 0xde 0xec6 0xe0 0xec2 0xe8 0xebd 0xed 0xeb8 0xf4 0xeb1 0xfb 0xea9 0x100 0xe9e 0x105 0xe8f 0x10a 0xe80 0x111 0xe78 0x116 0xe75 0x11d 0xe72 0x125 0xe6c 0x12a 0xe60 0x12e 0xe29 0x133 0xdc8 0x13b 0xd90 0x142 0xd4b 0x144 0xcfb 0x144 0xcc3 0x144 0xc9e 0x147 0xc83 0x147 0xc6c 0x147 0xc55 0x147 0xc45 0x147 0xc34 0x147 0xc25 0x147 0xc18 0x147 0xc0c 0x147 0xc07 0x147 0xbfb 0x147 0xbf2 0x147 0xbe7 0x147 0xbe1 0x147 0xbd8 0x147 0xbd5 0x147 0xbca 0x147 0xbc0 0x147 0xbba 0x147 0xbbb 0x147 0xbb3 0x147 0xba9 0x147 0xba7 0x147 0xba3 0x147 0xb97>;
			battery_profile_t1_num = <0x52>;
			battery_profile_t2 = <0x0 0x10e8 0x2 0x10cf 0x4 0x10bb 0x5 0x10a7 0x7 0x1095 0x9 0x1083 0xb 0x1071 0xd 0x105d 0xe 0x104d 0x10 0x103b 0x13 0x102a 0x15 0x1019 0x16 0x1008 0x18 0xff7 0x1a 0xfe8 0x1c 0xfda 0x1e 0xfc9 0x1f 0xfb9 0x21 0xfab 0x23 0xf9c 0x25 0xf8f 0x27 0xf84 0x28 0xf76 0x2a 0xf69 0x2c 0xf56 0x2e 0xf43 0x30 0xf31 0x31 0xf24 0x34 0xf19 0x36 0xf0e 0x38 0xf06 0x39 0xf00 0x3b 0xef8 0x3d 0xef0 0x3f 0xeea 0x41 0xee5 0x42 0xedd 0x44 0xed9 0x46 0xed2 0x48 0xecd 0x4a 0xec8 0x4b 0xec2 0x4d 0xebc 0x4f 0xeb5 0x51 0xea9 0x54 0xea1 0x55 0xe95 0x57 0xe85 0x59 0xe73 0x5b 0xe6c 0x5c 0xe6b 0x5e 0xe69 0x60 0xe67 0x62 0xe54 0x64 0xe0d 0x65 0xda9 0x67 0xd3f 0x68 0xc55 0x69 0xc01 0x69 0xbce 0x69 0xbb0 0x69 0xb99 0x69 0xb8e 0x69 0xb82 0x69 0xb76 0x69 0xb6d 0x69 0xb61 0x69 0xb5e 0x69 0xb54 0x69 0xb4b 0x69 0xb4b 0x69 0xb4b 0x69 0xb4b 0x69 0xb4b 0x69 0xb4b 0x69 0xb4b 0x69 0xb4b 0x69 0xb4b 0x69 0xb4b 0x69 0xb4b 0x69 0xb4b 0x69 0xb4b>;
			battery_profile_t2_num = <0x52>;
			battery_profile_t3 = <0x0 0x10eb 0x2 0x10d1 0x3 0x10bc 0x5 0x10a9 0x7 0x1094 0xa 0x1081 0xb 0x106e 0xd 0x105c 0xf 0x104a 0x10 0x1039 0x12 0x1027 0x14 0x1017 0x16 0x1006 0x17 0xff5 0x1a 0xfe5 0x1c 0xfd6 0x1d 0xfc6 0x1f 0xfb7 0x21 0xfaa 0x23 0xf9c 0x24 0xf90 0x26 0xf82 0x28 0xf76 0x29 0xf6b 0x2c 0xf5e 0x2e 0xf51 0x2f 0xf40 0x31 0xf2c 0x33 0xf1c 0x35 0xf11 0x36 0xf08 0x38 0xefe 0x3b 0xef8 0x3c 0xef0 0x3e 0xee9 0x40 0xee3 0x42 0xede 0x43 0xed8 0x45 0xed2 0x47 0xece 0x48 0xec8 0x4a 0xec1 0x4d 0xeb3 0x4f 0xeae 0x50 0xea6 0x52 0xe9e 0x54 0xe95 0x55 0xe8b 0x57 0xe7d 0x59 0xe6e 0x5b 0xe5e 0x5d 0xe5c 0x5f 0xe5b 0x61 0xe5a 0x62 0xe55 0x64 0xe29 0x66 0xddb 0x68 0xda7 0x69 0xd82 0x6b 0xd03 0x6d 0xc44 0x6d 0xc06 0x6d 0xbd9 0x6d 0xbb9 0x6d 0xba4 0x6e 0xb90 0x6e 0xb80 0x6e 0xb74 0x6e 0xb69 0x6e 0xb61 0x6e 0xb57 0x6e 0xb53 0x6e 0xb49 0x6e 0xb49 0x6e 0xb49 0x6e 0xb49 0x6e 0xb49 0x6e 0xb49 0x6e 0xb49 0x6e 0xb49 0x6e 0xb49 0x6e 0xb49>;
			battery_profile_t3_num = <0x52>;
			batterypseudo1 = <0xb>;
			batterypseudo100 = <0x5f>;
			car_tune_value = <0x76>;
			change_tracking_point = <0x1>;
			charge_tracking_time = <0x3c>;
			charging_full_current = <0x64>;
			charging_host_charger_current = <0xfde8>;
			close_poweroff_wakeup_period = <0x1e>;
			compatible = "mediatek,bat_meter";
			config_usb_if = <0x0>;
			current_detect_r_fg = <0xa>;
			cust_hw_cc = <0x0>;
			cust_poweron_delta_capacity_tolrance = <0x28>;
			cust_poweron_delta_hw_sw_ocv_capacity_tolrance = <0xa>;
			cust_poweron_delta_vbat_tolrance = <0x1e>;
			cust_poweron_low_capacity_tolrance = <0x5>;
			cust_poweron_max_vbat_tolrance = <0x5a>;
			cust_r_fg_offset = <0x0>;
			cust_r_sense = <0x38>;
			cust_tracking_point = <0x0>;
			difference_hwocv_rtc = <0x1e>;
			difference_hwocv_swocv = <0xa>;
			difference_swocv_rtc = <0xa>;
			difference_voltage_update = <0x14>;
			discharge_tracking_time = <0xa>;
			err_charge_temperature = <0xff>;
			fg_meter_resistance = <0x0>;
			fg_vbat_average_size = <0x12>;
			fixed_tbat_25 = <0x0>;
			high_battery_voltage_support = <0x0>;
			low_power_wakeup_period = <0x12c>;
			max_charge_temperature = <0x32>;
			max_charge_temperature_minus_x_degree = <0x2f>;
			max_swocv = <0x3>;
			md_sleep_current_check = <0x1>;
			min_charge_temperature = <0x0>;
			min_charge_temperature_plus_x_degree = <0x6>;
			minerroroffset = <0x3e8>;
			mtk_enable_aging_algorithm = <0x1>;
			mtk_temperature_recharge_support = <0x1>;
			non_std_ac_charger_current = <0xc350>;
			normal_wakeup_period = <0x1518>;
			npercent_tracking_time = <0x14>;
			oam_d5 = <0x1>;
			ocv_board_compesate = <0x0>;
			onehundred_percent_tracking_time = <0xa>;
			q_max_by_current = <0x0>;
			q_max_by_sys = <0x1>;
			q_max_neg_10 = <0x327>;
			q_max_neg_10_h_current = <0x317>;
			q_max_pos_0 = <0x348>;
			q_max_pos_0_h_current = <0x337>;
			q_max_pos_25 = <0xa93>;
			q_max_pos_25_h_current = <0xa5d>;
			q_max_pos_50 = <0xab7>;
			q_max_pos_50_h_current = <0xa80>;
			q_max_sys_voltage = <0xd16>;
			r_bat_sense = <0x4>;
			r_charger_1 = <0x14a>;
			r_charger_2 = <0x27>;
			r_fg_board_base = <0x3e8>;
			r_fg_board_slope = <0x3e8>;
			r_fg_value = <0xa>;
			r_i_sense = <0x4>;
			r_profile_t0 = <0x198 0x10cf 0x198 0x10b9 0x19f 0x10a5 0x1a9 0x1090 0x1ae 0x1079 0x1b8 0x1062 0x1cf 0x1049 0x1ea 0x1031 0x20d 0x1015 0x23d 0xff8 0x267 0xfe4 0x28a 0xfcf 0x2a3 0xfb3 0x2ad 0xf9d 0x2c1 0xf8d 0x2c9 0xf7f 0x2d0 0xf74 0x2dd 0xf66 0x2d8 0xf59 0x2e2 0xf49 0x2d5 0xf37 0x2df 0xf28 0x2e9 0xf1d 0x2ec 0xf11 0x2f8 0xf08 0x305 0xeff 0x30f 0xef6 0x323 0xeef 0x334 0xeea 0x343 0xee3 0x35f 0xede 0x378 0xed8 0x387 0xed4 0x39d 0xecf 0x3bb 0xecb 0x3cf 0xec5 0x3e8 0xebf 0x40b 0xeba 0x422 0xeb0 0x442 0xea8 0x451 0xe9e 0x46f 0xe93 0x490 0xe89 0x4ba 0xe81 0x4e7 0xe78 0x541 0xe72 0x596 0xe68 0x5ee 0xe51 0x622 0xe1d 0x652 0xdc6 0x684 0xd8a 0x64d 0xd74 0x61b 0xd60 0x5e6 0xd4c 0x5b4 0xd35 0x578 0xd1d 0x535 0xd04 0x503 0xcee 0x4d1 0xcdb 0x4ae 0xcca 0x483 0xcbb 0x468 0xcad 0x445 0xca2 0x433 0xc95 0x41d 0xc8c 0x3ff 0xc84 0x3fa 0xc79 0x3ed 0xc72 0x3d2 0xc6b 0x3c0 0xc60 0x3ac 0xc5a 0x37f 0xc55 0x37a 0xc4f 0x35f 0xc47 0x39d 0xc3d 0x37d 0xc35 0x37d 0xc35 0x37d 0xc35 0x37d 0xc35 0x37d 0xc35 0x37d 0xc35 0x37d 0xc35>;
			r_profile_t0_num = <0x52>;
			r_profile_t1 = <0x102 0x10dc 0x102 0x10bb 0x116 0x1094 0x12f 0x1072 0x14d 0x1059 0x157 0x1044 0x15e 0x1030 0x16d 0x1020 0x172 0x100d 0x172 0xffd 0x17c 0xff0 0x193 0xfe5 0x18b 0xfcf 0x193 0xfb7 0x193 0xfa3 0x19d 0xf95 0x1a2 0xf89 0x1a4 0xf7f 0x1a7 0xf73 0x19f 0xf64 0x19a 0xf53 0x190 0xf43 0x189 0xf33 0x189 0xf25 0x184 0xf18 0x18b 0xf0f 0x193 0xf06 0x195 0xefd 0x19f 0xef7 0x1a9 0xeef 0x1ae 0xee7 0x1bb 0xee3 0x1c2 0xedc 0x1d1 0xed7 0x1db 0xed2 0x1e3 0xece 0x1ea 0xec9 0x1f7 0xec6 0x208 0xec2 0x215 0xebd 0x221 0xeb8 0x233 0xeb1 0x24c 0xea9 0x258 0xe9e 0x260 0xe8f 0x267 0xe80 0x27b 0xe78 0x29e 0xe75 0x2c6 0xe72 0x2fd 0xe6c 0x348 0xe60 0x370 0xe29 0x393 0xdc8 0x438 0xd90 0x52b 0xd4b 0x523 0xcfb 0x49c 0xcc3 0x438 0xc9e 0x3f2 0xc83 0x3be 0xc6c 0x39d 0xc55 0x378 0xc45 0x35c 0xc34 0x32a 0xc25 0x314 0xc18 0x2fd 0xc0c 0x2bc 0xc07 0x2e9 0xbfb 0x2a8 0xbf2 0x2ad 0xbe7 0x28a 0xbe1 0x2ab 0xbd8 0x267 0xbd5 0x283 0xbca 0x294 0xbc0 0x27b 0xbba 0x212 0xbbb 0x280 0xbb3 0x253 0xba9 0x217 0xba7 0x1cf 0xba3 0x258 0xb97>;
			r_profile_t1_num = <0x52>;
			r_profile_t2 = <0x9b 0x10e8 0x9b 0x10cf 0x9b 0x10bb 0x9e 0x10a7 0x9e 0x1095 0xa3 0x1083 0xa5 0x1071 0xa5 0x105d 0xaa 0x104d 0xaa 0x103b 0xad 0x102a 0xad 0x1019 0xad 0x1008 0xb2 0xff7 0xb4 0xfe8 0xb9 0xfda 0xbc 0xfc9 0xbe 0xfb9 0xc8 0xfab 0xc8 0xf9c 0xcd 0xf8f 0xda 0xf84 0xd7 0xf76 0xd7 0xf69 0xc8 0xf56 0xbc 0xf43 0xad 0xf31 0xa8 0xf24 0xa3 0xf19 0xa0 0xf0e 0xa3 0xf06 0xa8 0xf00 0xaa 0xef8 0xaa 0xef0 0xaa 0xeea 0xb2 0xee5 0xaf 0xedd 0xb7 0xed9 0xb4 0xed2 0xb7 0xecd 0xb9 0xec8 0xb7 0xec2 0xb9 0xebc 0xb7 0xeb5 0xad 0xea9 0xad 0xea1 0xad 0xe95 0xad 0xe85 0xad 0xe73 0xaa 0xe6c 0xaf 0xe6b 0xb9 0xe69 0xc6 0xe67 0xcd 0xe54 0xd0 0xe0d 0xf0 0xda9 0x111 0xd3f 0x38c 0xc55 0x2c1 0xc01 0x253 0xbce 0x201 0xbb0 0x1d1 0xb99 0x19d 0xb8e 0x17c 0xb82 0x170 0xb76 0x168 0xb6d 0x14f 0xb61 0x113 0xb5e 0x13b 0xb54 0x11b 0xb4b 0x11b 0xb4b 0x11b 0xb4b 0x11b 0xb4b 0x11b 0xb4b 0x11b 0xb4b 0x11b 0xb4b 0x11b 0xb4b 0x11b 0xb4b 0x11b 0xb4b 0x11b 0xb4b 0x11b 0xb4b 0x11b 0xb4b>;
			r_profile_t2_num = <0x52>;
			r_profile_t3 = <0x7b 0x10eb 0x7b 0x10d1 0x80 0x10bc 0x82 0x10a9 0x82 0x1094 0x82 0x1081 0x80 0x106e 0x7d 0x105c 0x82 0x104a 0x85 0x1039 0x85 0x1027 0x8a 0x1017 0x8a 0x1006 0x8c 0xff5 0x8c 0xfe5 0x8f 0xfd6 0x8c 0xfc6 0x8f 0xfb7 0x94 0xfaa 0x99 0xf9c 0x9b 0xf90 0x9b 0xf82 0xa5 0xf76 0xaf 0xf6b 0xaf 0xf5e 0xb2 0xf51 0xaa 0xf40 0x94 0xf2c 0x87 0xf1c 0x87 0xf11 0x85 0xf08 0x85 0xefe 0x87 0xef8 0x87 0xef0 0x87 0xee9 0x8f 0xee3 0x91 0xede 0x94 0xed8 0x91 0xed2 0x99 0xece 0x96 0xec8 0x96 0xec1 0x85 0xeb3 0x8f 0xeae 0x8c 0xea6 0x8a 0xe9e 0x87 0xe95 0x87 0xe8b 0x85 0xe7d 0x85 0xe6e 0x82 0xe5e 0x82 0xe5c 0x8a 0xe5b 0x94 0xe5a 0xa0 0xe55 0x9e 0xe29 0xaa 0xddb 0xd0 0xda7 0xdc 0xd82 0x109 0xd03 0x357 0xc44 0x2d5 0xc06 0x258 0xbd9 0x210 0xbb9 0x1cc 0xba4 0x190 0xb90 0x17c 0xb80 0x163 0xb74 0x13b 0xb69 0x12f 0xb61 0x134 0xb57 0xff 0xb53 0x111 0xb49 0x111 0xb49 0x111 0xb49 0x111 0xb49 0x111 0xb49 0x111 0xb49 0x111 0xb49 0x111 0xb49 0x111 0xb49 0x111 0xb49>;
			r_profile_t3_num = <0x52>;
			rbat_pull_up_r = <0x5dc0>;
			rbat_pull_up_volt = <0x708>;
			recharge_tolerance = <0xa>;
			recharging_voltage = <0x100e>;
			shutdown_gauge0 = <0x1>;
			shutdown_gauge1_mins = <0x3c>;
			shutdown_gauge1_xmins = <0x1>;
			shutdown_system_voltage = <0xd48>;
			stop_charging_in_takling = <0x1>;
			sync_to_real_tracking_time = <0x3c>;
			sync_ui_soc_imm = <0x0>;
			talking_recharge_voltage = <0xed8>;
			talking_sync_time = <0x3c>;
			temperature_t = <0xff>;
			temperature_t0 = <0x6e>;
			temperature_t1 = <0x0>;
			temperature_t2 = <0x19>;
			temperature_t3 = <0x32>;
			usb_charger_current = <0xc350>;
			usb_charger_current_configured = <0xc350>;
			usb_charger_current_suspend = <0x0>;
			usb_charger_current_unconfigured = <0x1b58>;
			v_0percent_tracking = <0xd7a>;
			v_cc2topoff_thres = <0xfd2>;
			v_charger_enable = <0x0>;
			v_charger_max = <0x1964>;
			v_charger_min = <0x1130>;
			v_pre2cc_thres = <0xd48>;
			vbat_low_power_wakeup = <0xdac>;
			vbat_normal_wakeup = <0xe10>;
		};

		bat_notify {
			compatible = "mediatek,bat_notify";
		};

		battery {
			compatible = "mediatek,battery";
		};

		bpi_bsi_slv0@1021e000 {
			compatible = "mediatek,bpi_bsi_slv0";
			reg = <0x1021e000 0x1000>;
		};

		bpi_bsi_slv1@1021f000 {
			compatible = "mediatek,bpi_bsi_slv1";
			reg = <0x1021f000 0x6000>;
		};

		bpi_bsi_slv2@10225000 {
			compatible = "mediatek,bpi_bsi_slv2";
			reg = <0x10225000 0x1000>;
		};

		btcvsd@10001000 {
			compatible = "mediatek,audio_bt_cvsd";
			interrupts = <0x0 0xec 0x8>;
			offset = <0xf00 0x800 0xfd0 0xfd4 0xfd8>;
			reg = <0x10001000 0x1000 0x18000000 0x10000 0x18080000 0x8000>;
		};

		btif@1100c000 {
			clock-names = "btifc", "apdmac";
			clocks = <0x2 0x1b 0x2 0x2a>;
			compatible = "mediatek,btif";
			interrupts = <0x0 0x70 0x8>;
			reg = <0x1100c000 0x1000>;
		};

		btif_rx@11000800 {
			compatible = "mediatek,btif_rx";
			interrupts = <0x0 0x74 0x8>;
			reg = <0x11000800 0x80>;
		};

		btif_tx@11000780 {
			compatible = "mediatek,btif_tx";
			interrupts = <0x0 0x6f 0x8>;
			reg = <0x11000780 0x80>;
		};

		bus_dbg@10208000 {
			compatible = "mediatek,bus_dbg-v2";
			interrupts = <0x0 0x84 0x8>;
			reg = <0x10208000 0x1000>;
		};

		cam0@15004000 {
			compatible = "mediatek,cam0";
			reg = <0x15004000 0x1000>;
		};

		cam0_inner@1500d000 {
			compatible = "mediatek,cam0_inner";
			reg = <0x1500d000 0x1000>;
		};

		cam1@15005000 {
			compatible = "mediatek,cam1";
			interrupts = <0x0 0xd2 0x8>;
			reg = <0x15005000 0x1000>;
		};

		cam2@15006000 {
			compatible = "mediatek,cam2";
			interrupts = <0x0 0xd3 0x8>;
			reg = <0x15006000 0x1000>;
		};

		cam2_inner@1500e000 {
			compatible = "mediatek,cam2_inner";
			reg = <0x1500e000 0x1000>;
		};

		cam3@15007000 {
			compatible = "mediatek,cam3";
			interrupts = <0x0 0xd4 0x8>;
			reg = <0x15007000 0x1000>;
		};

		cam3_inner@1500f000 {
			compatible = "mediatek,cam3_inner";
			reg = <0x1500f000 0x1000>;
		};

		cam_cal_drv@0 {
			compatible = "mediatek,cam_cal_drv";
			main_bus = <0x2>;
			sub_bus = <0x2>;
		};

		camsv@15009000 {
			compatible = "mediatek,camsv";
			interrupts = <0x0 0xd5 0x8>;
			reg = <0x15009000 0x1000>;
		};

		ccci_off@0 {
			clock-names = "scp-sys-md1-main";
			clocks = <0x24 0x1>;
			compatible = "mediatek,ccci_off";
		};

		ccci_util_cfg {
			compatible = "mediatek,ccci_util_cfg";
			mediatek,md1-smem-size = <0x200000>;
			mediatek,md1md3-smem-size = <0x200000>;
			mediatek,md3-smem-size = <0x200000>;
			mediatek,version = <0x1>;
		};

		chipid@08000000 {
			compatible = "mediatek,chipid";
			reg = <0x8000000 0x4 0x8000004 0x4 0x8000008 0x4 0x800000c 0x4>;
		};

		consys@18070000 {
			clock-names = "conn";
			clocks = <0x24 0x3>;
			compatible = "mediatek,mt6755-consys";
			interrupts = <0x0 0xed 0x8 0x0 0xef 0x8>;
			pinctrl-0 = <0x1e>;
			pinctrl-1 = <0x62>;
			pinctrl-2 = <0x63>;
			pinctrl-3 = <0x64>;
			pinctrl-names = "default", "gps_lna_state_init", "gps_lna_state_oh", "gps_lna_state_ol";
			reg = <0x18070000 0x200 0x10007000 0x100 0x10000000 0x2000 0x10006000 0x1000>;
			status = "okay";
		};

		cpu_dbgapb {
			compatible = "mediatek,hw_dbg";
			num = <0x8>;
			reg = <0x10810000 0x1000 0x10910000 0x1000 0x10a10000 0x1000 0x10b10000 0x1000 0x10c10000 0x1000 0x10d10000 0x1000 0x10e10000 0x1000 0x10f10000 0x1000>;
		};

		cqdma@10212c00 {
			clock-names = "cqdma";
			clocks = <0x2 0x8>;
			compatible = "mediatek,mt-cqdma-v1";
			interrupts = <0x0 0x71 0x8 0x0 0x72 0x8>;
			nr_channel = <0x2>;
			reg = <0x10212c00 0x100 0x10212d00 0x100>;
		};

		dbgapb@10400000 {
			compatible = "mediatek,dbgapb";
			interrupts = <0x0 0x83 0x8>;
			reg = <0x10400000 0xc00000>;
		};

		dbgapb_base@1011a000 {
			compatible = "mediatek,dbgapb_base";
			reg = <0x1011a000 0x100>;
		};

		ddrphy@1000f000 {
			compatible = "mediatek,ddrphy";
			reg = <0x1000f000 0x1000>;
		};

		devapc@10207000 {
			clock-names = "devapc-main";
			clocks = <0x2 0x2c>;
			compatible = "mediatek,devapc";
			interrupts = <0x0 0x85 0x8>;
			reg = <0x10207000 0x1000>;
		};

		devapc_ao@1000e000 {
			compatible = "mediatek,devapc_ao";
			reg = <0x1000e000 0x1000>;
		};

		disp_aal@1400f000 {
			compatible = "mediatek,disp_aal";
			interrupts = <0x0 0xbf 0x8>;
			reg = <0x1400f000 0x1000>;
		};

		disp_ccorr@1400e000 {
			compatible = "mediatek,disp_ccorr";
			interrupts = <0x0 0xbe 0x8>;
			reg = <0x1400e000 0x1000>;
		};

		disp_color@1400d000 {
			compatible = "mediatek,disp_color";
			interrupts = <0x0 0xbd 0x8>;
			reg = <0x1400d000 0x1000>;
		};

		disp_dither@14011000 {
			compatible = "mediatek,disp_dither";
			interrupts = <0x0 0xc1 0x8>;
			reg = <0x14011000 0x1000>;
		};

		disp_gamma@14010000 {
			compatible = "mediatek,disp_gamma";
			interrupts = <0x0 0xc0 0x8>;
			reg = <0x14010000 0x1000>;
		};

		disp_ovl0@14008000 {
			compatible = "mediatek,disp_ovl0";
			interrupts = <0x0 0xb8 0x8>;
			reg = <0x14008000 0x1000>;
		};

		disp_ovl0_2l@14018000 {
			compatible = "mediatek,disp_ovl0_2l";
			interrupts = <0x0 0xc7 0x8>;
			reg = <0x14018000 0x1000>;
		};

		disp_ovl1@14009000 {
			compatible = "mediatek,disp_ovl1";
			interrupts = <0x0 0xb9 0x8>;
			reg = <0x14009000 0x1000>;
		};

		disp_ovl1_2l@14019000 {
			compatible = "mediatek,disp_ovl1_2l";
			interrupts = <0x0 0xc8 0x8>;
			reg = <0x14019000 0x1000>;
		};

		disp_pwm@1100e000 {
			compatible = "mediatek,disp_pwm";
			reg = <0x1100e000 0x1000>;
		};

		disp_rdma0@1400a000 {
			compatible = "mediatek,disp_rdma0";
			interrupts = <0x0 0xba 0x8>;
			reg = <0x1400a000 0x1000>;
		};

		disp_rdma1@1400b000 {
			compatible = "mediatek,disp_rdma1";
			interrupts = <0x0 0xbb 0x8>;
			reg = <0x1400b000 0x1000>;
		};

		disp_wdma0@1400c000 {
			compatible = "mediatek,disp_wdma0";
			interrupts = <0x0 0xbc 0x8>;
			reg = <0x1400c000 0x1000>;
		};

		disp_wdma1@14017000 {
			compatible = "mediatek,disp_wdma1";
			reg = <0x14017000 0x1000>;
		};

		dispsys@14008000 {
			clock-names = "DISP0_SMI_COMMON", "DISP0_SMI_LARB0", "DISP0_DISP_OVL0", "DISP0_DISP_OVL1", "DISP0_DISP_RDMA0", "DISP0_DISP_RDMA1", "DISP0_DISP_WDMA0", "DISP0_DISP_COLOR", "DISP0_DISP_CCORR", "DISP0_DISP_AAL", "DISP0_DISP_GAMMA", "DISP0_DISP_DITHER", "DISP0_DISP_UFOE_MOUT", "DISP0_DISP_WDMA1", "DISP0_DISP_2L_OVL0", "DISP0_DISP_2L_OVL1", "DISP0_DISP_OVL0_MOUT", "DISP1_DSI_ENGINE", "DISP1_DSI_DIGITAL", "DISP1_DPI_ENGINE", "DISP1_DPI_PIXEL", "DISP_PWM", "DISP_MTCMOS_CLK", "MUX_DPI0", "TVDPLL_D2", "TVDPLL_D4", "TVDPLL_D8", "TVDPLL_D16", "DPI_CK", "MUX_PWM", "UNIVPLL2_D4", "OSC_D2", "OSC_D8", "MUX_MM", "MM_VENCPLL", "SYSPLL2_D2";
			clocks = <0x25 0x1 0x25 0xc 0x25 0x19 0x25 0x1a 0x25 0x1b 0x25 0x1c 0x25 0x1d 0x25 0x1e 0x25 0x1f 0x25 0x20 0x25 0x21 0x25 0x22 0x25 0x24 0x25 0x25 0x25 0x26 0x25 0x27 0x25 0x28 0x25 0x29 0x25 0x2a 0x25 0x2b 0x25 0x2c 0x2 0x35 0x24 0x4 0x20 0x15 0x20 0x3d 0x20 0x3e 0x20 0x3f 0x20 0x40 0x20 0x51 0x20 0x1a 0x20 0x4a 0x20 0x2c 0x20 0x2e 0x20 0x4 0x20 0x4e 0x20 0x37>;
			compatible = "mediatek,dispsys";
			interrupts = <0x0 0x0 0x8 0x0 0xb8 0x8 0x0 0xb9 0x8 0x0 0xba 0x8 0x0 0xbb 0x8 0x0 0xbc 0x8 0x0 0xbd 0x8 0x0 0xbe 0x8 0x0 0xbf 0x8 0x0 0xc0 0x8 0x0 0xc1 0x8 0x0 0xc2 0x8 0x0 0xc3 0x8 0x0 0x0 0x8 0x0 0xb1 0x8 0x0 0x0 0x8 0x0 0x0 0x8 0x0 0xc5 0x8 0x0 0xc7 0x8 0x0 0xc8 0x8 0x0 0x0 0x8>;
			reg = <0x14000000 0x1000 0x14008000 0x1000 0x14009000 0x1000 0x1400a000 0x1000 0x1400b000 0x1000 0x1400c000 0x1000 0x1400d000 0x1000 0x1400e000 0x1000 0x1400f000 0x1000 0x14010000 0x1000 0x14011000 0x1000 0x14012000 0x1000 0x14013000 0x1000 0x1100e000 0x1000 0x14014000 0x1000 0x14015000 0x1000 0x14016000 0x1000 0x14017000 0x1000 0x14018000 0x1000 0x14019000 0x1000 0x10215000 0x1000>;
		};

		dpi0@14013000 {
			compatible = "mediatek,dpi0";
			interrupts = <0x0 0xc3 0x8>;
			reg = <0x14013000 0x1000>;
		};

		dramc@10004000 {
			compatible = "mediatek,dramc";
			interrupts = <0x0 0x95 0x2>;
			reg = <0x10004000 0x1000>;
		};

		dramc_nao@1020e000 {
			compatible = "mediatek,dramc_nao";
			reg = <0x1020e000 0x1000>;
		};

		dsi0@14012000 {
			compatible = "mediatek,dsi0";
			interrupts = <0x0 0xc2 0x8>;
			reg = <0x14012000 0x1000>;
		};

		dvfsp@10227000 {
			clock-names = "i2c";
			clocks = <0x2 0xd>;
			compatible = "mediatek,mt6755-dvfsp";
			interrupts = <0x0 0x98 0x8>;
			reg = <0x10227000 0x1000 0x11c000 0xf80>;
		};

		efusec@10206000 {
			compatible = "mediatek,efusec";
			reg = <0x10206000 0x1000>;
		};

		eintc@1000b000 {
			#interrupt-cells = <0x2>;
			compatible = "mediatek,mt-eic";
			interrupt-controller;
			interrupts = <0x0 0x9b 0x4>;
			linux,phandle = <0x1c>;
			mediatek,builtin_eint_hw_deb = <0x91 0x8 0x90>;
			mediatek,debtime_setting_array = <0x0 0x80 0x1 0x100 0x2 0x200 0x3 0x400 0x4 0x4000 0x5 0x8000 0x6 0x10000 0x7 0x20000 0x8 0x40000 0x9 0x80000>;
			mediatek,debtime_setting_entry = <0xa>;
			mediatek,deint_possible_irq = <0xbf 0xc0 0xc1 0xc2>;
			mediatek,mapping_table_entry = <0x0>;
			mediatek,max_deint_cnt = <0x4>;
			mediatek,max_eint_num = <0xa0>;
			mediatek,max_hw_deb_cnt = <0x10>;
			phandle = <0x1c>;
			reg = <0x1000b000 0x1000>;

			MD1_SIM1_HOT_PLUG_EINT@0 {
				compatible = "mediatek,MD1_SIM1_HOT_PLUG_EINT-eint";
				debounce = <0x0 0x186a0>;
				dedicated = <0x0 0x0>;
				interrupts = <0x0 0x8>;
				sockettype = <0x0 0x0>;
				src_pin = <0x0 0x1>;
				status = "okay";
			};
		};

		emi@10203000 {
			compatible = "mediatek,emi";
			interrupts = <0x0 0x87 0x2>;
			reg = <0x10203000 0x1000>;
		};

		emi_mpu@10226000 {
			compatible = "mediatek,emi_mpu";
			interrupts = <0x0 0x75 0x4>;
			reg = <0x10226000 0x1000>;
		};

		fdvt@1500b000 {
			clock-names = "FD-SCP_SYS_DIS", "FD-SCP_SYS_ISP", "FD-MM_DISP0_SMI_COMMON", "FD-IMG_IMAGE_FD";
			clocks = <0x24 0x4 0x24 0x6 0x25 0x1 0x27 0xc>;
			compatible = "mediatek,fdvt";
			interrupts = <0x0 0xd7 0x8>;
			reg = <0x1500b000 0x1000>;
		};

		fhctl@1000cf00 {
			compatible = "mediatek,fhctl";
			reg = <0x1000cf00 0x100>;
		};

		flashlight {
			compatible = "mediatek,mt6755-flashlight";
			pinctrl-0 = <0x6e>;
			pinctrl-1 = <0x6f>;
			pinctrl-2 = <0x70>;
			pinctrl-3 = <0x71>;
			pinctrl-names = "flash_low", "flash_high", "torch_low", "torch_high";
			status = "okay";
		};

		g_sensor@0 {
			compatible = "mediatek,g_sensor";
			pinctrl-0 = <0x72>;
			pinctrl-1 = <0x73>;
			pinctrl-names = "pin_default", "pin_cfg";
			status = "okay";
		};

		gce@10212000 {
			ap_dma_base = <0x11000000 0x17 0xffff0000>;
			apxgpt2_count = <0x10008028>;
			audio_base = <0x11220000 0x12 0xffff0000>;
			buf_underrun_event_0 = <0x36>;
			buf_underrun_event_1 = <0x37>;
			camsv_1_pass1_done = <0x87>;
			camsv_2_pass1_done = <0x86>;
			clock-names = "GCE";
			clocks = <0x2 0x8>;
			compatible = "mediatek,gce";
			conn_peri_base = <0x18000000 0x7 0xffff0000>;
			disp_2l_ovl0_frame_done = <0x2a>;
			disp_2l_ovl0_sof = <0x13>;
			disp_2l_ovl1_frame_done = <0x2b>;
			disp_2l_ovl1_sof = <0x14>;
			disp_aal_frame_done = <0x24>;
			disp_aal_sof = <0xe>;
			disp_ccorr_frame_done = <0x23>;
			disp_ccorr_sof = <0xd>;
			disp_color_frame_done = <0x22>;
			disp_color_sof = <0xc>;
			disp_dither_base = <0x14010000 0x2 0xffff0000>;
			disp_dither_frame_done = <0x26>;
			disp_dither_sof = <0x10>;
			disp_dpi0_frame_done = <0x27>;
			disp_dsi0_frame_done = <0x29>;
			disp_gamma_frame_done = <0x25>;
			disp_gamma_sof = <0xf>;
			disp_mutex_reg = <0x14014000 0x1000>;
			disp_ovl0_frame_done = <0x1d>;
			disp_ovl0_sof = <0x7>;
			disp_ovl1_frame_done = <0x1e>;
			disp_ovl1_sof = <0x8>;
			disp_pwm0_sof = <0x12>;
			disp_rdma0_frame_done = <0x1f>;
			disp_rdma0_sof = <0x9>;
			disp_rdma1_frame_done = <0x20>;
			disp_rdma1_sof = <0xa>;
			disp_wdma0_frame_done = <0x21>;
			disp_wdma0_sof = <0xb>;
			disp_wdma1_frame_done = <0x28>;
			disp_wdma1_sof = <0x11>;
			dsi0_te_event = <0x38>;
			g3d_config_base = <0x13000000 0x0 0xffff0000>;
			gcpu_base = <0x10210000 0xf 0xffff0000>;
			imgsys_base = <0x15000000 0x4 0xffff0000>;
			infra_na3_base = <0x10030000 0xb 0xffff0000>;
			infra_na4_base = <0x10040000 0xc 0xffff0000>;
			interrupts = <0x0 0x8f 0x8 0x0 0x90 0x8>;
			isp_frame_done_p1_0 = <0x85>;
			isp_frame_done_p1_1 = <0x84>;
			isp_frame_done_p2_0 = <0x83>;
			isp_frame_done_p2_1 = <0x82>;
			isp_frame_done_p2_2 = <0x81>;
			jpgdec_done = <0x103>;
			jpgenc_done = <0x102>;
			kp_base = <0x10010000 0x9 0xffff0000>;
			max_prefetch_cnt = <0x4>;
			mcucfg_base = <0x10200000 0xe 0xffff0000>;
			mdp_color_frame_done = <0x1c>;
			mdp_color_sof = <0x6>;
			mdp_rdma0_frame_done = <0x15>;
			mdp_rdma0_sof = <0x0>;
			mdp_rsz0_frame_done = <0x16>;
			mdp_rsz0_sof = <0x1>;
			mdp_rsz1_frame_done = <0x17>;
			mdp_rsz1_sof = <0x2>;
			mdp_tdshp_frame_done = <0x18>;
			mdp_tdshp_sof = <0x3>;
			mdp_wdma_frame_done = <0x19>;
			mdp_wdma_sof = <0x4>;
			mdp_wrot_read_frame_done = <0x1b>;
			mdp_wrot_sof = <0x5>;
			mdp_wrot_write_frame_done = <0x1a>;
			mm_na_base = <0x14020000 0x3 0xffff0000>;
			mmsys_config_base = <0x14000000 0x1 0xffff0000>;
			msdc0_base = <0x11230000 0x13 0xffff0000>;
			msdc1_base = <0x11240000 0x14 0xffff0000>;
			msdc2_base = <0x11250000 0x15 0xffff0000>;
			msdc3_base = <0x11260000 0x16 0xffff0000>;
			prefetch_size = <0xa0 0x20 0x20 0x20>;
			reg = <0x10212000 0x1000>;
			scp_base = <0x10050000 0xd 0xffff0000>;
			scp_sram_base = <0x10020000 0xa 0xffff0000>;
			seninf_cam0_fifo_full = <0x89>;
			seninf_cam1_2_3_fifo_full = <0x88>;
			sram_share_cnt = <0x1>;
			sram_share_engine = <0x8>;
			sram_share_event = <0x1cc>;
			stream_done_0 = <0x2c>;
			stream_done_1 = <0x2d>;
			stream_done_2 = <0x2e>;
			stream_done_3 = <0x2f>;
			stream_done_4 = <0x30>;
			stream_done_5 = <0x31>;
			stream_done_6 = <0x32>;
			stream_done_7 = <0x33>;
			stream_done_8 = <0x34>;
			stream_done_9 = <0x35>;
			topckgen_base = <0x10000000 0x8 0xffff0000>;
			usb0_base = <0x11200000 0x10 0xffff0000>;
			usb_sif_base = <0x11210000 0x11 0xffff0000>;
			vdec_gcon_base = <0x16000000 0x5 0xffff0000>;
			venc_128byte_cnt_done = <0x105>;
			venc_done = <0x101>;
			venc_gcon_base = <0x17000000 0x6 0xffff0000>;
			venc_mb_done = <0x104>;
		};

		gcpu@10210000 {
			compatible = "mediatek,gcpu";
			interrupts = <0x0 0x96 0x8>;
			reg = <0x10210000 0x1000>;
		};

		gcpu_rsa@1021a000 {
			compatible = "mediatek,gcpu_rsa";
			reg = <0x1021a000 0x1000>;
		};

		gpio {
			GPIO_FDD_BAND_SUPPORT_DETECT_1ST_PIN = <0xe>;
			GPIO_FDD_BAND_SUPPORT_DETECT_2ND_PIN = <0xf>;
			GPIO_FDD_BAND_SUPPORT_DETECT_3RD_PIN = <0x10>;
			GPIO_FDD_BAND_SUPPORT_DETECT_4TH_PIN = <0x11>;
			GPIO_FDD_BAND_SUPPORT_DETECT_5TH_PIN = <0x14>;
			GPIO_SIM1_HOT_PLUG = <0x2e>;
			GPIO_SIM1_SCLK = <0x27>;
			GPIO_SIM1_SIO = <0x29>;
			GPIO_SIM1_SRST = <0x28>;
			GPIO_SIM2_HOT_PLUG = <0x2d>;
			GPIO_SIM2_SCLK = <0x26>;
			GPIO_SIM2_SIO = <0x24>;
			GPIO_SIM2_SRST = <0x25>;
			compatible = "mediatek,gpio_usage_mapping";
		};

		gpio@10005000 {
			compatible = "mediatek,gpio";
			reg = <0x10005000 0x1000>;
		};

		gps {
			compatible = "mediatek,gps";
		};

		gpufreq {
			clock-names = "clk_mux", "clk_main_parent", "clk_sub_parent";
			clocks = <0x20 0x7 0x20 0x23 0x20 0x2f>;
			compatible = "mediatek,mt6755-gpufreq";
		};

		gyroscope@0 {
			compatible = "mediatek,gyroscope";
		};

		hacc@1000a000 {
			clock-names = "sej-main";
			clocks = <0x2 0x5>;
			compatible = "mediatek,hacc";
			interrupts = <0x0 0xad 0x8>;
			reg = <0x1000a000 0x1000>;
		};

		i2c@11007000 {
			#address-cells = <0x1>;
			#size-cells = <0x0>;
			cell-index = <0x0>;
			clock-div = <0xa>;
			clock-names = "main", "dma";
			clocks = <0x2 0xa 0x2 0x2a>;
			compatible = "mediatek,mt6755-i2c", "mediatek,i2c0";
			interrupts = <0x0 0x54 0x8>;
			pinctrl-0 = <0x2e>;
			pinctrl-1 = <0x2f>;
			pinctrl-2 = <0x30>;
			pinctrl-3 = <0x31>;
			pinctrl-4 = <0x32>;
			pinctrl-5 = <0x33>;
			pinctrl-6 = <0x34 0x35 0x36>;
			pinctrl-names = "default", "gt1x_power_rst_on", "gt1x_power_rst_off", "gt1x_eint_as_int", "gt1x_eint_output0", "gt1x_eint_output1", "gt1x_tp_id_sleep";
			reg = <0x11007000 0x1000 0x11000100 0x80>;
			status = "okay";

			cap_touch@14 {
				compatible = "mediatek,cap_touch";
				reg = <0x14>;
				status = "okay";
			};

			i2c_bl_lm3697@36 {
				compatible = "mediatek,i2c_bl_lm3697";
				reg = <0x36>;
				status = "okay";
			};

			i2c_lcd_bias@3e {
				compatible = "mediatek,i2c_lcd_bias";
				reg = <0x3e>;
				status = "okay";
			};

			ts4621@60 {
				compatible = "st,ts4621";
				reg = <0x60>;
				status = "okay";
			};
		};

		i2c@11008000 {
			#address-cells = <0x1>;
			#size-cells = <0x0>;
			cell-index = <0x1>;
			clock-div = <0xa>;
			clock-names = "main", "dma";
			clocks = <0x2 0xb 0x2 0x2a>;
			compatible = "mediatek,mt6755-i2c", "mediatek,i2c1";
			interrupts = <0x0 0x55 0x8>;
			reg = <0x11008000 0x1000 0x11000180 0x80>;

			alsps-tmd2745@60 {
				als_gain1 = <0x21>;
				als_gain2 = <0x14>;
				compatible = "oppo,tmd2745";
				eint_gpio = <0x6>;
				i2c_addr = <0x39 0x0 0x0 0x0>;
				i2c_num = <0x1>;
				is_batch_supported_als = <0x0>;
				is_batch_supported_ps = <0x0>;
				polling_mode_als = <0x1>;
				polling_mode_ps = <0x0>;
				power_id = <0xffff>;
				power_vol = <0x0>;
				reg = <0x39>;
				status = "okay";
			};

			alsps@53 {
				compatible = "mediatek,alsps";
				reg = <0x53>;
				status = "okay";
			};

			camera_sub@10 {
				compatible = "mediatek,camera_sub";
				reg = <0x10>;
				status = "okay";
			};

			gsensor-kx023@1f {
				compatible = "oppo,gsensor-kx023";
				direction = <0x6>;
				firlen = <0x0>;
				i2c_num = <0x1>;
				is_batch_supported = <0x1>;
				is_eint_supported = <0x1>;
				power_id = <0xffff>;
				power_vol = <0x0>;
				reg = <0x1f>;
				status = "okay";
			};

			gsensor-lis3dh@19 {
				compatible = "oppo,gsensor-lis3dh";
				direction = <0x6>;
				filter_in_vib = <0x1>;
				firlen = <0x0>;
				i2c_num = <0x1>;
				is_batch_supported = <0x1>;
				is_eint_supported = <0x1>;
				power_id = <0xffff>;
				power_vol = <0x0>;
				reg = <0x19>;
				status = "okay";
			};

			gyro@68 {
				compatible = "mediatek,gyro";
				reg = <0x68>;
				status = "okay";
			};

			msensor-mmc3524x@30 {
				compatible = "mediatek,mmc3524x";
				direction = <0x7>;
				i2c_add = <0x30 0x0 0x0 0x0>;
				i2c_num = <0x1>;
				power_id = <0xffff>;
				power_vol = <0x0>;
				reg = <0x30>;
				status = "okay";
			};

			msensor@0c {
				compatible = "mediatek,msensor";
				reg = <0xc>;
				status = "okay";
			};

			swithing_charger@6b {
				compatible = "mediatek,swithing_charger";
				reg = <0x6b>;
				status = "okay";
			};
		};

		i2c@11009000 {
			#address-cells = <0x1>;
			#size-cells = <0x0>;
			cell-index = <0x2>;
			clock-div = <0xa>;
			clock-names = "main", "dma";
			clocks = <0x2 0xc 0x2 0x2a>;
			compatible = "mediatek,mt6755-i2c", "mediatek,i2c2";
			interrupts = <0x0 0x56 0x8>;
			reg = <0x11009000 0x1000 0x11000200 0x80>;

			camera_main@10 {
				compatible = "mediatek,camera_main";
				reg = <0x10>;
				status = "okay";
			};

			camera_main_af@0c {
				compatible = "mediatek,camera_main_af";
				reg = <0xc>;
				status = "okay";
			};

			strobe_main@63 {
				compatible = "mediatek,strobe_main";
				reg = <0x63>;
				status = "okay";
			};

			strobe_main_2@67 {
				compatible = "mediatek,strobe_main_2";
				reg = <0x67>;
				status = "okay";
			};
		};

		i2c@1100f000 {
			#address-cells = <0x1>;
			#size-cells = <0x0>;
			cell-index = <0x3>;
			clock-div = <0xa>;
			clock-names = "main", "dma";
			clocks = <0x2 0xd 0x2 0x2a>;
			compatible = "mediatek,mt6755-i2c", "mediatek,i2c3";
			interrupts = <0x0 0x57 0x8>;
			reg = <0x1100f000 0x1000 0x11000280 0x80>;

			mt6311@6b {
				compatible = "mediatek,ext_buck";
				reg = <0x6b>;
			};
		};

		i2c@11011000 {
			#address-cells = <0x1>;
			#size-cells = <0x0>;
			cell-index = <0x4>;
			clock-div = <0xa>;
			clock-names = "main", "dma";
			clocks = <0x2 0x3a 0x2 0x2a>;
			compatible = "mediatek,mt6755-i2c", "mediatek,i2c4";
			interrupts = <0x0 0x58 0x8>;
			reg = <0x11011000 0x1000 0x11000300 0x80>;

			bq24196-charger@6b {
				compatible = "oppo,bq24196-charger";
				pinctrl-0 = <0x3c>;
				pinctrl-1 = <0x3d>;
				pinctrl-2 = <0x3e>;
				pinctrl-names = "default", "charger_gpio_as_output_low", "charger_gpio_as_output_high";
				qcom,batt_capacity_mah = <0xbb8>;
				qcom,charger_hv_thr = <0x16a8>;
				qcom,charger_lv_thr = <0xd48>;
				qcom,check_batt_full_by_sw;
				qcom,chg_ctrl_by_calling;
				qcom,chg_ctrl_by_camera;
				qcom,chg_ctrl_by_lcd;
				qcom,cold_bat_decidegc = <0x1e>;
				qcom,cold_vfloat_sw_limit = <0xf5a>;
				qcom,cool_bat_decidegc = <0x32>;
				qcom,cool_vfloat_sw_limit = <0x10e0>;
				qcom,external_gauge;
				qcom,hot_bat_decidegc = <0x212>;
				qcom,input_current_calling_ma = <0x5dc>;
				qcom,input_current_camera_ma = <0x4b0>;
				qcom,input_current_charger_ma = <0x7d0>;
				qcom,input_current_led_ma = <0x4b0>;
				qcom,input_current_led_ma_forcmcc = <0x1f4>;
				qcom,input_current_usb_ma = <0x1f4>;
				qcom,iterm-disabled = <0x0>;
				qcom,iterm-ma = <0x96>;
				qcom,little_cold_bat_decidegc = <0x0>;
				qcom,little_cold_vfloat_sw_limit = <0x10e0>;
				qcom,little_cool_bat_decidegc = <0x78>;
				qcom,little_cool_vfloat_sw_limit = <0x10e0>;
				qcom,max_chg_time_sec = <0x8ca0>;
				qcom,non_standard_fastchg_current_ma = <0x200>;
				qcom,non_standard_vfloat_mv = <0xfa0>;
				qcom,non_standard_vfloat_sw_limit = <0xf6e>;
				qcom,normal_bat_decidegc = <0xdc>;
				qcom,normal_vfloat_sw_limit = <0x10e0>;
				qcom,recharge-mv = <0x64>;
				qcom,removed_bat_decidegc = <0xbe>;
				qcom,suspend_after_full;
				qcom,temp_cold_fastchg_current_ma = <0x16c>;
				qcom,temp_cold_recharge-mv = <0xb4>;
				qcom,temp_cold_vfloat_mv = <0xf8c>;
				qcom,temp_cool_fastchg_current_ma_high = <0x2d5>;
				qcom,temp_cool_fastchg_current_ma_low = <0x1b3>;
				qcom,temp_cool_vfloat_mv = <0x1112>;
				qcom,temp_little_cold_fastchg_current_ma = <0x1b3>;
				qcom,temp_little_cold_recharge-mv = <0xdc>;
				qcom,temp_little_cold_vfloat_mv = <0x1112>;
				qcom,temp_little_cool_fastchg_current_ma = <0x579>;
				qcom,temp_little_cool_vfloat_mv = <0x1112>;
				qcom,temp_normal_fastchg_current_ma = <0x79e>;
				qcom,temp_normal_vfloat_mv_normalchg = <0x1112>;
				qcom,temp_normal_vfloat_mv_voocchg = <0x1100>;
				qcom,temp_warm_fastchg_current_ma = <0x2d5>;
				qcom,temp_warm_vfloat_mv = <0xff0>;
				qcom,usb_switch_gpio = <0x52>;
				qcom,vbatt_full_thr = <0x1130>;
				qcom,vbatt_hv_thr = <0x1194>;
				qcom,vfloat_step_mv = <0x10>;
				qcom,warm_bat_decidegc = <0x1c2>;
				qcom,warm_vfloat_sw_limit = <0xfbe>;
				reg = <0x6b 0x0>;
				status = "okay";
			};

			nfc@28 {
				compatible = "mediatek,nfc";
				reg = <0x28>;
				status = "okay";
			};
		};

		icusb@11270000 {
			compatible = "mediatek,icusb";
			reg = <0x11270000 0x10000>;
		};

		imgsys@15000000 {
			#clock-cells = <0x1>;
			compatible = "mediatek,mt6755-imgsys";
			linux,phandle = <0x27>;
			phandle = <0x27>;
			reg = <0x15000000 0x1000>;
		};

		infra_mbist@1020d000 {
			compatible = "mediatek,infra_mbist";
			reg = <0x1020d000 0x1000>;
		};

		infra_md@1021d000 {
			compatible = "mediatek,infra_md";
			reg = <0x1021d000 0x1000>;
		};

		infracfg@10201000 {
			compatible = "mediatek,infracfg";
			reg = <0x10201000 0x1000>;
		};

		infracfg_ao@10001000 {
			compatible = "mediatek,infracfg_ao";
			interrupts = <0x0 0x88 0x1>;
			reg = <0x10001000 0x1000>;
		};

		infrasys@10001000 {
			#clock-cells = <0x1>;
			compatible = "mediatek,mt6755-infrasys";
			linux,phandle = <0x2>;
			phandle = <0x2>;
			reg = <0x10001000 0x1000>;
		};

		iocfg_0@10002000 {
			compatible = "mediatek,iocfg_0";
			reg = <0x10002000 0x1000>;
		};

		iocfg_1@10002200 {
			compatible = "mediatek,iocfg_1";
			reg = <0x10002200 0x200>;
		};

		iocfg_2@10002400 {
			compatible = "mediatek,iocfg_2";
			reg = <0x10002400 0x200>;
		};

		iocfg_3@10002600 {
			compatible = "mediatek,iocfg_3";
			reg = <0x10002600 0x200>;
		};

		iocfg_4@10002800 {
			compatible = "mediatek,iocfg_4";
			reg = <0x10002800 0x200>;
		};

		iocfg_5@10002a00 {
			compatible = "mediatek,iocfg_5";
			reg = <0x10002a00 0x200>;
		};

		irtx@1100d000 {
			clock-div = <0x1>;
			clock-frequency = <0x18cba80>;
			clock-names = "clk-irtx-main";
			clocks = <0x2 0x33>;
			compatible = "mediatek,irtx";
			interrupts = <0x0 0x7f 0x8>;
			pwm_ch = <0x3>;
			reg = <0x1100d000 0x1000>;
		};

		irtx_pwm {
			compatible = "mediatek,irtx-pwm";
			pinctrl-0 = <0x38>;
			pinctrl-1 = <0x39>;
			pinctrl-2 = <0x3a>;
			pinctrl-3 = <0x3b>;
			pinctrl-names = "irtx_gpio_led_default", "irtx_gpio_led_set", "irtx_gpio_en_default", "irtx_gpio_en_set";
			pwm_ch = <0x2>;
			pwm_data_invert = <0x0>;
			status = "okay";
		};

		ispsys@15004000 {
			clock-names = "CG_SCP_SYS_DIS", "CG_SCP_SYS_ISP", "CG_DISP0_SMI_COMMON", "CG_IMAGE_CAM_SMI", "CG_IMAGE_CAM_CAM", "CG_IMAGE_SEN_TG", "CG_IMAGE_SEN_CAM", "CG_IMAGE_CAM_SV", "CG_IMAGE_LARB2_SMI";
			clocks = <0x24 0x4 0x24 0x6 0x25 0x1 0x27 0x6 0x27 0x7 0x27 0x8 0x27 0x9 0x27 0xa 0x27 0x1>;
			compatible = "mediatek,ispsys";
			interrupts = <0x0 0xd2 0x8 0x0 0xd3 0x8 0x0 0xd4 0x8 0x0 0xd5 0x8 0x0 0xd6 0x8>;
			reg = <0x15004000 0x9000 0x1500d000 0x1000 0x15000000 0x10000 0x10217000 0x3000 0x10002000 0x1000>;
		};

		jpgdec@17004000 {
			clock-names = "disp-mtcmos", "disp-smi", "venc-mtcmos", "venc-larb", "venc-jpgdec";
			clocks = <0x24 0x4 0x25 0x1 0x24 0x8 0x28 0x1 0x28 0x9>;
			compatible = "mediatek,jpgdec";
			interrupts = <0x0 0xcd 0x8>;
			reg = <0x17004000 0x1000>;
		};

		jpgenc@17003000 {
			clock-names = "disp-mtcmos", "disp-smi", "venc-mtcmos", "venc-larb", "venc-jpgenc";
			clocks = <0x24 0x4 0x25 0x1 0x24 0x8 0x28 0x1 0x28 0x8>;
			compatible = "mediatek,jpgenc";
			interrupts = <0x0 0xcc 0x8>;
			reg = <0x17003000 0x1000>;
		};

		kd_camera_hw1@15008000 {
			clock-names = "TOP_CAMTG_SEL", "TOP_MUX_SCAM", "TOP_UNIVPLL_D26", "TOP_UNIVPLL2_D2";
			clocks = <0x20 0x8 0x20 0x16 0x20 0x45 0x20 0x49>;
			compatible = "mediatek,camera_hw";
			pinctrl-0 = <0x55>;
			pinctrl-1 = <0x56>;
			pinctrl-10 = <0x5f>;
			pinctrl-11 = <0x60>;
			pinctrl-12 = <0x61>;
			pinctrl-2 = <0x57>;
			pinctrl-3 = <0x58>;
			pinctrl-4 = <0x59>;
			pinctrl-5 = <0x5a>;
			pinctrl-6 = <0x5b>;
			pinctrl-7 = <0x5c>;
			pinctrl-8 = <0x5d>;
			pinctrl-9 = <0x5e>;
			pinctrl-names = "default", "cam0_rst0", "cam0_rst1", "cam0_pnd0", "cam0_pnd1", "cam1_rst0", "cam1_rst1", "cam1_pnd0", "cam1_pnd1", "cam_mclk1_on", "cam_mclk1_off", "cam_mclk2_on", "cam_mclk2_off";
			reg = <0x15008000 0x1000>;
			status = "okay";
			vcama-supply = <0x51>;
			vcama_main2-supply = <0x51>;
			vcama_sub-supply = <0x51>;
			vcamaf-supply = <0x54>;
			vcamaf_main2-supply = <0x54>;
			vcamaf_sub-supply = <0x54>;
			vcamd-supply = <0x52>;
			vcamio-supply = <0x53>;
			vcamio_main2-supply = <0x53>;
			vcamio_sub-supply = <0x53>;
		};

		kd_camera_hw2@15008000 {
			compatible = "mediatek,camera_hw2";
			reg = <0x15008000 0x1000>;
		};

		keypad@10010000 {
			compatible = "mediatek,mt6755-keypad", "mediatek,kp";
			interrupts = <0x0 0xa4 0x2>;
			mediatek,kpd-hw-dl-key0 = <0x0>;
			mediatek,kpd-hw-dl-key1 = <0x1>;
			mediatek,kpd-hw-dl-key2 = <0x8>;
			mediatek,kpd-hw-factory-key = <0x0>;
			mediatek,kpd-hw-init-map = <0x73 0x72 0x0 0x0 0x0 0x0 0x0 0x0 0x0 0x0 0x0 0x0 0x0 0x0 0x0 0x0 0x0 0x0 0x0 0x0 0x0 0x0 0x0 0x0 0x0 0x0 0x0 0x0 0x0 0x0 0x0 0x0 0x0 0x0 0x0 0x0 0x0 0x0 0x0 0x0 0x0 0x0 0x0 0x0 0x0 0x0 0x0 0x0 0x0 0x0 0x0 0x0 0x0 0x0 0x0 0x0 0x0 0x0 0x0 0x0 0x0 0x0 0x0 0x0 0x0 0x0 0x0 0x0 0x0 0x0 0x0 0x0>;
			mediatek,kpd-hw-map-num = <0x48>;
			mediatek,kpd-hw-pwrkey = <0x8>;
			mediatek,kpd-hw-recovery-key = <0x1>;
			mediatek,kpd-key-debounce = <0x400>;
			mediatek,kpd-pwkey-gpio-din = <0x0>;
			mediatek,kpd-pwrkey-eint-gpio = <0x0>;
			mediatek,kpd-sw-pwrkey = <0x74>;
			mediatek,kpd-use-extend-type = <0x0>;
			pinctrl-0 = <0x22>;
			pinctrl-1 = <0x23>;
			pinctrl-names = "volume_up_as_int", "volume_down_as_int";
			reg = <0x10010000 0x1000>;
			status = "okay";
		};

		kpd_volume_down {
			compatible = "mediatek, VOLUME_DOWN-eint";
			debounce = <0x68 0x7a1200>;
			interrupt-parent = <0x1c>;
			interrupts = <0x68 0x8>;
			status = "okay";
		};

		kpd_volume_up {
			compatible = "mediatek, VOLUME_UP-eint";
			debounce = <0x4d 0x7a1200>;
			interrupt-parent = <0x1c>;
			interrupts = <0x4d 0x8>;
			status = "okay";
		};

		lastbus@10200000 {
			compatible = "mediatek,lastbus";
			reg = <0x10200000 0x1000 0x10003000 0x1000>;
		};

		lastpc@10200000 {
			compatible = "mediatek,lastpc-v1";
			reg = <0x10200000 0x200>;
		};

		m4u@10205000 {
			cell-index = <0x0>;
			clock-names = "smi_common", "m4u_disp0_smi_larb0", "m4u_vdec0_vdec", "m4u_vdec1_larb", "m4u_img_image_larb2_smi", "m4u_venc_venc", "m4u_venc_larb", "m4u_mtcmos_ven", "m4u_mtcmos_vde", "m4u_mtcmos_isp", "m4u_mtcmos_dis";
			clocks = <0x25 0x1 0x25 0xc 0x26 0x1 0x26 0x2 0x27 0x1 0x28 0x7 0x28 0x1 0x24 0x8 0x24 0x7 0x24 0x6 0x24 0x4>;
			compatible = "mediatek,m4u";
			interrupts = <0x0 0x93 0x8>;
			reg = <0x10205000 0x1000>;
		};

		m_baro_pl@0 {
			compatible = "mediatek,m_baro_pl";
		};

		mali@13040000 {
			clock-frequency = <0x29b92700>;
			clock-names = "mfg-main", "mfg-smi-common", "mtcmos-mfg", "mtcmos-display";
			clocks = <0x37 0x1 0x25 0x1 0x24 0x5 0x24 0x4>;
			compatible = "arm,malit860", "arm,mali-t86x", "arm,malit8xx", "arm,mali-midgard";
			interrupt-names = "JOB", "MMU", "GPU";
			interrupts = <0x0 0xda 0x8 0x0 0xd9 0x8 0x0 0xd8 0x8>;
			reg = <0x13040000 0x4000>;
		};

		mcucfg@10200000 {
			compatible = "mediatek,mcucfg";
			interrupts = <0x0 0x0 0x8>;
			reg = <0x10200000 0x1000>;
		};

		md2md_md1_ccif0@10211000 {
			compatible = "mediatek,md2md_md1_ccif0";
			reg = <0x10211000 0x1000>;
		};

		md2md_md2_ccif0@10213000 {
			compatible = "mediatek,md2md_md2_ccif0";
			reg = <0x10213000 0x1000>;
		};

		md_ccif0@1020a000 {
			compatible = "mediatek,md_ccif0";
			reg = <0x1020a000 0x1000>;
		};

		md_ccif1@1020c000 {
			compatible = "mediatek,md_ccif1";
			reg = <0x1020c000 0x1000>;
		};

		mdcldma@10014000 {
			clock-names = "scp-sys-md1-main";
			clocks = <0x24 0x1>;
			compatible = "mediatek,mdcldma";
			interrupts = <0x0 0xde 0x4 0x0 0x8b 0x8 0x0 0xdf 0x2>;
			mediatek,cldma_capability = <0x6>;
			mediatek,md_id = <0x0>;
			mediatek,md_smem_size = <0x100000>;
			reg = <0x10014000 0x1e00 0x10015000 0x1e00 0x1021b000 0x1e00 0x1021c000 0x1e00 0x10209000 0x1000 0x1020a000 0x1000>;
		};

		mdp_color@14007000 {
			clock-names = "MDP_COLOR";
			clocks = <0x25 0x23>;
			compatible = "mediatek,mdp_color";
			interrupts = <0x0 0xc6 0x8>;
			reg = <0x14007000 0x1000>;
		};

		mdp_rdma@14001000 {
			clock-names = "MDP_RDMA";
			clocks = <0x25 0x12>;
			compatible = "mediatek,mdp_rdma";
			interrupts = <0x0 0xb2 0x8>;
			reg = <0x14001000 0x1000>;
		};

		mdp_rsz0@14002000 {
			clock-names = "MDP_RSZ0";
			clocks = <0x25 0x13>;
			compatible = "mediatek,mdp_rsz0";
			interrupts = <0x0 0xb3 0x8>;
			reg = <0x14002000 0x1000>;
		};

		mdp_rsz1@14003000 {
			clock-names = "MDP_RSZ1";
			clocks = <0x25 0x14>;
			compatible = "mediatek,mdp_rsz1";
			interrupts = <0x0 0xb4 0x8>;
			reg = <0x14003000 0x1000>;
		};

		mdp_tdshp@14006000 {
			clock-names = "MDP_TDSHP";
			clocks = <0x25 0x15>;
			compatible = "mediatek,mdp_tdshp";
			interrupts = <0x0 0xb5 0x8>;
			reg = <0x14006000 0x1000>;
		};

		mdp_wdma@14004000 {
			clock-names = "MDP_WDMA";
			clocks = <0x25 0x16>;
			compatible = "mediatek,mdp_wdma";
			interrupts = <0x0 0xb6 0x8>;
			reg = <0x14004000 0x1000>;
		};

		mdp_wrot@14005000 {
			clock-names = "MDP_WROT";
			clocks = <0x25 0x17>;
			compatible = "mediatek,mdp_wrot";
			interrupts = <0x0 0xb7 0x8>;
			reg = <0x14005000 0x1000>;
		};

		met_cci400@10390000 {
			compatible = "mediatek,met_cci400";
			reg = <0x10390000 0x10000>;
		};

		met_dramc_nao@1020e000 {
			compatible = "mediatek,met_dramc_nao";
			reg = <0x1020e000 0x1000>;
		};

		met_emi@10203000 {
			compatible = "mediatek,met_emi";
			reg = <0x10203000 0x1000>;
		};

		met_smi@14016000 {
			clock-names = "smi-common", "smi-larb0", "img-larb2", "vdec1-larb", "venc-venc", "venc-larb", "mtcmos-ven", "mtcmos-vde", "mtcmos-isp", "mtcmos-dis";
			clocks = <0x25 0x1 0x25 0xc 0x27 0x1 0x26 0x2 0x28 0x7 0x28 0x1 0x24 0x8 0x24 0x7 0x24 0x6 0x24 0x4>;
			compatible = "mediatek,met_smi";
			reg = <0x14016000 0x1000 0x14015000 0x1000 0x16010000 0x10000 0x15001000 0x1000 0x17001000 0x1000>;
		};

		mfg_dfp@13020000 {
			compatible = "mediatek,mfg_dfp";
			reg = <0x13020000 0x1000>;
		};

		mfg_vad@13001000 {
			compatible = "mediatek,mfg_vad";
			reg = <0x13001000 0x1000>;
		};

		mfgcfg@13000000 {
			compatible = "mediatek,mfgcfg";
			reg = <0x13000000 0x1000>;
		};

		mfgsys@13000000 {
			#clock-cells = <0x1>;
			compatible = "mediatek,mt6755-mfgsys";
			linux,phandle = <0x37>;
			phandle = <0x37>;
			reg = <0x13000000 0x1000>;
		};

		mhl@0 {
			compatible = "mediatek,extd_dev";
		};

		mipi_rx@1500c000 {
			compatible = "mediatek,mipi_rx";
			reg = <0x1500c000 0x1000>;
		};

		mipi_rx_ana_csi0@10217000 {
			compatible = "mediatek,mipi_rx_ana_csi0";
			reg = <0x10217000 0x1000>;
		};

		mipi_rx_ana_csi1@10218000 {
			compatible = "mediatek,mipi_rx_ana_csi1";
			reg = <0x10218000 0x1000>;
		};

		mipi_tx0@10215000 {
			compatible = "mediatek,mipi_tx0";
			reg = <0x10215000 0x1000>;
		};

		mm_mutex@14014000 {
			compatible = "mediatek,mm_mutex";
			interrupts = <0x0 0xb1 0x8>;
			reg = <0x14014000 0x1000>;
		};

		mmsys_config@14000000 {
			#clock-cells = <0x1>;
			clock-names = "CAM_MDP";
			clocks = <0x25 0x11>;
			compatible = "mediatek,mmsys_config", "mediatek,mt6755-mmsys";
			interrupts = <0x0 0xc4 0x8>;
			linux,phandle = <0x25>;
			phandle = <0x25>;
			reg = <0x14000000 0x1000>;
		};

		modem_temp_share@10018000 {
			compatible = "mediatek,modem_temp_share";
			reg = <0x10018000 0x1000>;
		};

		msensor@0 {
			compatible = "mediatek,msensor";
			pinctrl-0 = <0x76>;
			pinctrl-1 = <0x77>;
			pinctrl-names = "reset_pin_low", "reset_pin_high";
			status = "okay";
		};

		mt3326-gps@ffffffff {
			compatible = "mediatek,mt3326-gps";
		};

		mt_soc_btcvsd_rx_pcm@10001000 {
			compatible = "mediatek,mt_soc_btcvsd_rx_pcm";
		};

		mt_soc_btcvsd_tx_pcm@10001000 {
			compatible = "mediatek,mt_soc_btcvsd_tx_pcm";
		};

		mt_soc_codec_dummy_name@11220000 {
			compatible = "mediatek,mt_soc_codec_dummy";
		};

		mt_soc_codec_name@11220000 {
			compatible = "mediatek,mt_soc_codec_63xx";
			use_hp_depop_flow = <0x0>;
			use_ul_260k = <0x0>;
		};

		mt_soc_dai_name@11220000 {
			compatible = "mediatek,mt_soc_dai_stub";
		};

		mt_soc_dl1_awb_pcm@11220000 {
			compatible = "mediatek,mt_soc_pcm_dl1_awb";
		};

		mt_soc_dl1_pcm@11220000 {
			clock-names = "aud_afe_clk", "aud_i2s_clk", "aud_dac_clk", "aud_dac_predis_clk", "aud_adc_clk", "aud_apll22m_clk", "aud_apll24m_clk", "aud_apll1_tuner_clk", "aud_apll2_tuner_clk", "aud_tml_clk", "aud_apll1_div0_clk", "aud_apll2_div0_clk", "scp_sys_aud", "aud_infra_clk", "aud_peri_26m_clk", "aud_mux1_clk", "aud_mux2_clk", "top_ad_apll1_clk", "top_ad_apll2_clk", "top_mux_audio_int", "top_sys_pll1_d4", "apmixed_apll1_clk", "apmixed_apll2_clk", "top_clk26m_clk";
			clocks = <0x3f 0x1 0x3f 0x2 0x3f 0x8 0x3f 0x9 0x3f 0x7 0x3f 0x3 0x3f 0x4 0x3f 0x6 0x3f 0x5 0x3f 0xa 0x3f 0xb 0x3f 0xc 0x24 0x9 0x2 0x30 0x2 0x37 0x20 0x18 0x20 0x19 0x20 0x21 0x20 0x22 0x20 0x12 0x20 0x34 0x40 0x9 0x40 0xa 0x41>;
			compatible = "mediatek,mt_soc_pcm_dl1";
			interrupts = <0x0 0x8e 0x8>;
			pinctrl-0 = <0x42>;
			pinctrl-1 = <0x43>;
			pinctrl-2 = <0x44>;
			pinctrl-3 = <0x45>;
			pinctrl-4 = <0x46>;
			pinctrl-5 = <0x47>;
			pinctrl-6 = <0x48>;
			pinctrl-7 = <0x49>;
			pinctrl-8 = <0x4a>;
			pinctrl-names = "default", "audpmicclk-mode0", "audpmicclk-mode1", "audi2s1-mode0", "audi2s1-mode1", "spk-pa-en-pullhigh", "spk-pa-en-pulllow", "boost-en-pullhigh", "boost-en-pulllow";
			reg = <0x11220000 0x1000>;
			status = "okay";
		};

		mt_soc_dl2_pcm@11220000 {
			compatible = "mediatek,mt_soc_pcm_dl2";
		};

		mt_soc_dummy_pcm@11220000 {
			compatible = "mediatek,mt_soc_pcm_dummy";
		};

		mt_soc_fm_i2s_awb_pcm@11220000 {
			compatible = "mediatek,mt_soc_pcm_fm_i2s_awb";
		};

		mt_soc_fm_i2s_pcm@11220000 {
			compatible = "mediatek,mt_soc_pcm_fm_i2s";
		};

		mt_soc_fm_mrgtx_pcm@11220000 {
			compatible = "mediatek,mt_soc_pcm_fmtx";
		};

		mt_soc_hdmi_pcm@11220000 {
			compatible = "mediatek,mt_soc_pcm_hdmi";
		};

		mt_soc_hp_impedance_pcm@11220000 {
			compatible = "mediatek,mt_soc_pcm_hp_impedance";
		};

		mt_soc_i2s0_awb_pcm@11220000 {
			compatible = "mediatek,mt_soc_pcm_i2s0_awb";
		};

		mt_soc_i2s0_pcm@11220000 {
			compatible = "mediatek,mt_soc_pcm_dl1_i2s0";
		};

		mt_soc_i2s0dl1_pcm@11220000 {
			compatible = "mediatek,mt_soc_pcm_dl1_i2s0dl1";
		};

		mt_soc_mrgrx_awb_pcm@11220000 {
			compatible = "mediatek,mt_soc_pcm_mrgrx_awb";
		};

		mt_soc_mrgrx_pcm@11220000 {
			compatible = "mediatek,mt_soc_pcm_mrgrx";
		};

		mt_soc_offload_gdma@11220000 {
			compatible = "mediatek,mt_soc_pcm_offload_gdma";
		};

		mt_soc_routing_dai_name@11220000 {
			compatible = "mediatek,mt_soc_dai_routing";
		};

		mt_soc_routing_pcm@11220000 {
			compatible = "mediatek,mt_soc_pcm_routing";
			i2s1clk-gpio = <0x7 0x6>;
			i2s1dat-gpio = <0x5 0x6>;
			i2s1mclk-gpio = <0x9 0x6>;
			i2s1ws-gpio = <0x6 0x6>;
		};

		mt_soc_tdmrx_pcm@11220000 {
			compatible = "mediatek,mt_soc_tdm_capture";
		};

		mt_soc_ul1_pcm@11220000 {
			compatible = "mediatek,mt_soc_pcm_capture";
		};

		mt_soc_ul2_pcm@11220000 {
			compatible = "mediatek,mt_soc_pcm_capture2";
		};

		mt_soc_uldlloopback_pcm@11220000 {
			compatible = "mediatek,mt_soc_pcm_uldlloopback";
		};

		mt_soc_voice_md1@11220000 {
			compatible = "mediatek,mt_soc_pcm_voice_md1";
		};

		mt_soc_voice_md1_bt@11220000 {
			compatible = "mediatek,mt_soc_pcm_voice_md1_bt";
		};

		mt_soc_voice_md2@11220000 {
			compatible = "mediatek,mt_soc_pcm_voice_md2";
		};

		mt_soc_voice_md2_bt@11220000 {
			compatible = "mediatek,mt_soc_pcm_voice_md2_bt";
		};

		mt_soc_voip_bt_in@11220000 {
			compatible = "mediatek,mt_soc_pcm_bt_dai";
		};

		mt_soc_voip_bt_out@11220000 {
			compatible = "mediatek,mt_soc_pcm_dl1_bt";
		};

		mtkfb {
			compatible = "mediatek,mtkfb";
			pinctrl-0 = <0x1e>;
			pinctrl-1 = <0x78>;
			pinctrl-10 = <0x81>;
			pinctrl-11 = <0x82>;
			pinctrl-12 = <0x83>;
			pinctrl-2 = <0x79>;
			pinctrl-3 = <0x7a>;
			pinctrl-4 = <0x7b>;
			pinctrl-5 = <0x7c>;
			pinctrl-6 = <0x7d>;
			pinctrl-7 = <0x7e>;
			pinctrl-8 = <0x7f>;
			pinctrl-9 = <0x80>;
			pinctrl-names = "default", "mode_te_gpio", "mode_te_te", "lcm_rst_out0_gpio", "lcm_rst_out1_gpio", "lcd_bias_enp0_gpio", "lcd_bias_enp1_gpio", "lcd_bias_enn0_gpio", "lcd_bias_enn1_gpio", "lcd_bl_en0_gpio", "lcd_bl_en1_gpio", "lcm_ldo_en0_gpio", "lcm_ldo_en1_gpio";
			status = "okay";
		};

		nfcC@0 {
			compatible = "mediatek,nfc-gpio-v2";
			gpio-eint = <0x1b>;
			gpio-irq = <0x1a>;
			gpio-rst = <0x19>;
			gpio-ven = <0x1c>;
			pinctrl-0 = <0x1e>;
			pinctrl-1 = <0x65>;
			pinctrl-2 = <0x66>;
			pinctrl-3 = <0x67>;
			pinctrl-4 = <0x68>;
			pinctrl-5 = <0x69>;
			pinctrl-6 = <0x6a>;
			pinctrl-7 = <0x6b>;
			pinctrl-names = "default", "ven_high", "ven_low", "rst_high", "rst_low", "eint_high", "eint_low", "irq_init";
			status = "okay";
		};

		oppo_devinfo {
			Hw,sub_hwid_1 = <0xb 0x51 0x0>;
			Hw,sub_hwid_2 = <0xb 0x1b 0x0>;
			compatible = "oppo, device_info";
			pinctrl-0 = <0x89>;
			pinctrl-1 = <0x8a 0x8b>;
			pinctrl-2 = <0x8c 0x8d>;
			pinctrl-names = "default", "hw_sub_id_sleep", "hw_sub_id_active";
		};

		perisys@10003000 {
			#clock-cells = <0x1>;
			compatible = "mediatek,mt6755-perisys";
			reg = <0x10003000 0x1000>;
		};

		pinctrl@10005000 {
			#gpio-cells = <0x2>;
			compatible = "mediatek,mt6755-pinctrl";
			gpio-controller;
			linux,phandle = <0xb>;
			mediatek,pctl-regmap = <0x1d>;
			phandle = <0xb>;
			pins-are-numbered;
			reg = <0x10005000 0x1000>;

			accdeteint2default {
				linux,phandle = <0x6c>;
				phandle = <0x6c>;
			};

			active@id1 {
				linux,phandle = <0x8c>;
				phandle = <0x8c>;

				pins_cmd_dat {
					bias-pull-up = <0x0>;
					input-enable;
					pins = <0x5100>;
					slew-rate = <0x0>;
				};
			};

			active@id2 {
				linux,phandle = <0x8d>;
				phandle = <0x8d>;

				pins_cmd_dat {
					bias-pull-up = <0x0>;
					input-enable;
					pins = <0x1b00>;
					slew-rate = <0x0>;
				};
			};

			alspsdefaultcfg {
				linux,phandle = <0x74>;
				phandle = <0x74>;
			};

			alspspincfg {
				linux,phandle = <0x75>;
				phandle = <0x75>;

				pins_cmd_dat {
					bias-pull-up = <0x0>;
					pins = <0x600>;
					slew-rate = <0x0>;
				};
			};

			audboosthigh {
				linux,phandle = <0x49>;
				phandle = <0x49>;

				pins_cmd_dat {
					output-high;
					pins = <0x1800>;
					slew-rate = <0x1>;
				};
			};

			audboostlow {
				linux,phandle = <0x4a>;
				phandle = <0x4a>;

				pins_cmd_dat {
					output-low;
					pins = <0x1800>;
					slew-rate = <0x1>;
				};
			};

			audi2s1mode0 {
				linux,phandle = <0x45>;
				phandle = <0x45>;

				pins_cmd0_dat {
					pins = <0x700>;
				};

				pins_cmd1_dat {
					pins = <0x600>;
				};

				pins_cmd2_dat {
					pins = <0x500>;
				};
			};

			audi2s1mode1 {
				linux,phandle = <0x46>;
				phandle = <0x46>;

				pins_cmd0_dat {
					pins = <0x702>;
				};

				pins_cmd1_dat {
					pins = <0x602>;
				};

				pins_cmd2_dat {
					pins = <0x502>;
				};
			};

			audiodefault {
				linux,phandle = <0x42>;
				phandle = <0x42>;
			};

			audspkedlow {
				linux,phandle = <0x48>;
				phandle = <0x48>;

				pins_cmd_dat {
					output-low;
					pins = <0x3d00>;
					slew-rate = <0x1>;
				};
			};

			audspkenhigh {
				linux,phandle = <0x47>;
				phandle = <0x47>;

				pins_cmd_dat {
					output-high;
					pins = <0x3d00>;
					slew-rate = <0x1>;
				};
			};

			cam0@0 {
				linux,phandle = <0x56>;
				phandle = <0x56>;

				pins_cmd_dat {
					output-low;
					pins = <0x6e00>;
					slew-rate = <0x1>;
				};
			};

			cam0@1 {
				linux,phandle = <0x57>;
				phandle = <0x57>;

				pins_cmd_dat {
					output-high;
					pins = <0x6e00>;
					slew-rate = <0x1>;
				};
			};

			cam0@2 {
				linux,phandle = <0x58>;
				phandle = <0x58>;

				pins_cmd_dat {
					output-low;
					pins = <0x6b00>;
					slew-rate = <0x1>;
				};
			};

			cam0@3 {
				linux,phandle = <0x59>;
				phandle = <0x59>;

				pins_cmd_dat {
					output-high;
					pins = <0x6b00>;
					slew-rate = <0x1>;
				};
			};

			cam1@0 {
				linux,phandle = <0x5a>;
				phandle = <0x5a>;

				pins_cmd_dat {
					output-low;
					pins = <0x6f00>;
					slew-rate = <0x1>;
				};
			};

			cam1@1 {
				linux,phandle = <0x5b>;
				phandle = <0x5b>;

				pins_cmd_dat {
					output-high;
					pins = <0x6f00>;
					slew-rate = <0x1>;
				};
			};

			cam1@2 {
				linux,phandle = <0x5c>;
				phandle = <0x5c>;

				pins_cmd_dat {
					output-low;
					pins = <0x6c00>;
					slew-rate = <0x1>;
				};
			};

			cam1@3 {
				linux,phandle = <0x5d>;
				phandle = <0x5d>;

				pins_cmd_dat {
					output-high;
					pins = <0x6c00>;
					slew-rate = <0x1>;
				};
			};

			cam1@4 {

				pins_cmd_dat {
					output-low;
					pins = <0x5200>;
					slew-rate = <0x1>;
				};
			};

			cam1@5 {

				pins_cmd_dat {
					output-high;
					pins = <0x5200>;
					slew-rate = <0x1>;
				};
			};

			camdefault {
				linux,phandle = <0x55>;
				phandle = <0x55>;
			};

			charger_gpio_as_output_high {
				linux,phandle = <0x3e>;
				phandle = <0x3e>;

				pins_cmd_dat {
					output-high;
					pins = <0x5200>;
					slew-rate = <0x1>;
				};
			};

			charger_gpio_as_output_low {
				linux,phandle = <0x3d>;
				phandle = <0x3d>;

				pins_cmd_dat {
					output-low;
					pins = <0x5200>;
					slew-rate = <0x1>;
				};
			};

			default {
				linux,phandle = <0x1e>;
				phandle = <0x1e>;
			};

			default@hw_sub_id {
				linux,phandle = <0x89>;
				phandle = <0x89>;
			};

			drvvbus_default {
				linux,phandle = <0x4e>;
				phandle = <0x4e>;
			};

			drvvbus_high {
				linux,phandle = <0x50>;
				phandle = <0x50>;

				pins_cmd_dat {
					output-high;
					pins = <0x2b01>;
					slew-rate = <0x1>;
				};
			};

			drvvbus_low {
				linux,phandle = <0x4f>;
				phandle = <0x4f>;

				pins_cmd_dat {
					output-low;
					pins = <0x2b01>;
					slew-rate = <0x1>;
				};
			};

			eint0default {
				linux,phandle = <0x3c>;
				phandle = <0x3c>;
			};

			eint@0 {
				linux,phandle = <0x84>;
				phandle = <0x84>;

				pins_cmd_dat {
					bias-disable;
					pins = <0x100>;
					slew-rate = <0x0>;
				};
			};

			eint@1 {
				linux,phandle = <0x31>;
				phandle = <0x31>;

				pins_cmd_dat {
					bias-disable;
					pins = <0x100>;
					slew-rate = <0x0>;
				};
			};

			eint@2 {
				linux,phandle = <0x6d>;
				phandle = <0x6d>;

				pins_cmd_dat {
					bias-disable;
					pins = <0x200>;
					slew-rate = <0x0>;
				};
			};

			eint_output0 {
				linux,phandle = <0x32>;
				phandle = <0x32>;

				pins_cmd_dat {
					output-low;
					pins = <0x100>;
					slew-rate = <0x1>;
				};
			};

			eint_output1 {
				linux,phandle = <0x33>;
				phandle = <0x33>;

				pins_cmd_dat {
					output-high;
					pins = <0x100>;
					slew-rate = <0x1>;
				};
			};

			eintoutput0 {
				linux,phandle = <0x85>;
				phandle = <0x85>;

				pins_cmd_dat {
					output-low;
					pins = <0x100>;
					slew-rate = <0x1>;
				};
			};

			eintoutput1 {
				linux,phandle = <0x86>;
				phandle = <0x86>;

				pins_cmd_dat {
					output-high;
					pins = <0x100>;
					slew-rate = <0x1>;
				};
			};

			flash@0 {
				linux,phandle = <0x6e>;
				phandle = <0x6e>;

				pins_cmd_dat {
					output-low;
					pins = <0x900>;
					slew-rate = <0x1>;
				};
			};

			flash@1 {
				linux,phandle = <0x6f>;
				phandle = <0x6f>;

				pins_cmd_dat {
					output-high;
					pins = <0x900>;
					slew-rate = <0x1>;
				};
			};

			flash@2 {
				linux,phandle = <0x70>;
				phandle = <0x70>;

				pins_cmd_dat {
					output-low;
					pins = <0x800>;
					slew-rate = <0x1>;
				};
			};

			flash@3 {
				linux,phandle = <0x71>;
				phandle = <0x71>;

				pins_cmd_dat {
					output-high;
					pins = <0x800>;
					slew-rate = <0x1>;
				};
			};

			gpslna@0 {
				linux,phandle = <0x62>;
				phandle = <0x62>;

				pins_cmd_dat {
					bias-disable;
					output-low;
					pins = <0x7200>;
					slew-rate = <0x1>;
				};
			};

			gpslna@1 {
				linux,phandle = <0x63>;
				phandle = <0x63>;

				pins_cmd_dat {
					output-high;
					pins = <0x7200>;
					slew-rate = <0x1>;
				};
			};

			gpslna@2 {
				linux,phandle = <0x64>;
				phandle = <0x64>;

				pins_cmd_dat {
					output-low;
					pins = <0x7200>;
					slew-rate = <0x1>;
				};
			};

			gsensordefaultcfg {
				linux,phandle = <0x72>;
				phandle = <0x72>;
			};

			gsensorpincfg {
				linux,phandle = <0x73>;
				phandle = <0x73>;

				pins_cmd_dat {
					bias-pull-up = <0x0>;
					pins = <0x400>;
					slew-rate = <0x0>;
				};
			};

			iddig_default {
				linux,phandle = <0x4b>;
				phandle = <0x4b>;
			};

			iddig_init {
				linux,phandle = <0x4c>;
				phandle = <0x4c>;

				pins_cmd_dat {
					bias-pull-up = <0x0>;
					pins = <0x1702>;
					slew-rate = <0x0>;
				};
			};

			iddig_output_low {
				linux,phandle = <0x4d>;
				phandle = <0x4d>;

				pins_cmd_dat {
					output-low;
					pins = <0x1700>;
					slew-rate = <0x1>;
				};
			};

			irtx_gpio_en_def@gpio104 {
				linux,phandle = <0x3a>;
				phandle = <0x3a>;

				pins_cmd_dat {
					bias-disable;
					input-schmitt-enable = <0x0>;
					output-low;
					pins = <0x6800>;
					slew-rate = <0x1>;
				};
			};

			irtx_gpio_en_set@gpio104 {
				linux,phandle = <0x3b>;
				phandle = <0x3b>;

				pins_cmd_dat {
					output-high;
					pins = <0x6800>;
					slew-rate = <0x1>;
				};
			};

			irtx_gpio_led_def@gpio116 {
				linux,phandle = <0x38>;
				phandle = <0x38>;

				pins_cmd_dat {
					bias-disable;
					input-schmitt-enable = <0x0>;
					output-low;
					pins = <0x7400>;
					slew-rate = <0x1>;
				};
			};

			irtx_gpio_led_set@gpio116 {
				linux,phandle = <0x39>;
				phandle = <0x39>;

				pins_cmd_dat {
					output-high;
					pins = <0x7402>;
					slew-rate = <0x1>;
				};
			};

			lcd_bias_enn0_gpio {
				linux,phandle = <0x7e>;
				phandle = <0x7e>;

				pins_cmd_dat {
					output-low;
					pins = <0x500>;
					slew-rate = <0x1>;
				};
			};

			lcd_bias_enn1_gpio {
				linux,phandle = <0x7f>;
				phandle = <0x7f>;

				pins_cmd_dat {
					output-high;
					pins = <0x500>;
					slew-rate = <0x1>;
				};
			};

			lcd_bias_enp0_gpio {
				linux,phandle = <0x7c>;
				phandle = <0x7c>;

				pins_cmd_dat {
					output-low;
					pins = <0xc00>;
					slew-rate = <0x1>;
				};
			};

			lcd_bias_enp1_gpio {
				linux,phandle = <0x7d>;
				phandle = <0x7d>;

				pins_cmd_dat {
					output-high;
					pins = <0xc00>;
					slew-rate = <0x1>;
				};
			};

			lcd_bl_en0_gpio {
				linux,phandle = <0x80>;
				phandle = <0x80>;

				pins_cmd_dat {
					output-low;
					pins = <0xb00>;
					slew-rate = <0x1>;
				};
			};

			lcd_bl_en1_gpio {
				linux,phandle = <0x81>;
				phandle = <0x81>;

				pins_cmd_dat {
					output-high;
					pins = <0xb00>;
					slew-rate = <0x1>;
				};
			};

			lcm_ldo_en0_gpio {
				linux,phandle = <0x82>;
				phandle = <0x82>;

				pins_cmd_dat {
					output-low;
					pins = <0x5500>;
					slew-rate = <0x1>;
				};
			};

			lcm_ldo_en1_gpio {
				linux,phandle = <0x83>;
				phandle = <0x83>;

				pins_cmd_dat {
					output-high;
					pins = <0x5500>;
					slew-rate = <0x1>;
				};
			};

			lcm_rst_out0_gpio {
				linux,phandle = <0x7a>;
				phandle = <0x7a>;

				pins_cmd_dat {
					output-low;
					pins = <0x9e00>;
					slew-rate = <0x1>;
				};
			};

			lcm_rst_out1_gpio {
				linux,phandle = <0x7b>;
				phandle = <0x7b>;

				pins_cmd_dat {
					output-high;
					pins = <0x9e00>;
					slew-rate = <0x1>;
				};
			};

			mclk1@0 {
				linux,phandle = <0x5e>;
				phandle = <0x5e>;

				pins_cmd_dat {
					pins = <0xa101>;
					slew-rate = <0x1>;
				};
			};

			mclk1@1 {
				linux,phandle = <0x5f>;
				phandle = <0x5f>;

				pins_cmd_dat {
					pins = <0xa100>;
					slew-rate = <0x1>;
				};
			};

			mclk2@0 {
				linux,phandle = <0x60>;
				phandle = <0x60>;

				pins_cmd_dat {
					pins = <0x6d01>;
					slew-rate = <0x1>;
				};
			};

			mclk2@1 {
				linux,phandle = <0x61>;
				phandle = <0x61>;

				pins_cmd_dat {
					pins = <0x6d00>;
					slew-rate = <0x1>;
				};
			};

			mmc0@default {
				linux,phandle = <0x3>;
				phandle = <0x3>;

				pins_clk {
					drive-strength = [02];
				};

				pins_cmd {
					drive-strength = [02];
				};

				pins_dat {
					drive-strength = [02];
				};

				pins_ds {
					drive-strength = [02];
				};

				pins_rst {
					drive-strength = [02];
				};
			};

			mmc0@register_default {
				cmd_edge = [00];
				cmdrddly = [00];
				cmdrrddly = [00];
				datrddly = <0x0 0x0>;
				datwrddly = [00];
				linux,phandle = <0x4>;
				phandle = <0x4>;
				rdata_edge = [01];
				wdata_edge = [01];
			};

			mmc1@ddr50 {
				linux,phandle = <0x9>;
				phandle = <0x9>;

				pins_clk {
					drive-strength = [03];
				};

				pins_cmd {
					drive-strength = [02];
				};

				pins_dat {
					drive-strength = [02];
				};
			};

			mmc1@default {
				linux,phandle = <0x6>;
				phandle = <0x6>;

				pins_clk {
					drive-strength = [03];
				};

				pins_cmd {
					drive-strength = [05];
				};

				pins_dat {
					drive-strength = [03];
				};
			};

			mmc1@register_default {
				cmd_edge = [01];
				cmdrddly = [00];
				cmdrrddly = [00];
				datrddly = <0x0 0x0>;
				datwrddly = [00];
				linux,phandle = <0xa>;
				phandle = <0xa>;
				rdata_edge = [01];
				wdata_edge = [01];
			};

			mmc1@sdr104 {
				linux,phandle = <0x7>;
				phandle = <0x7>;

				pins_clk {
					drive-strength = [07];
				};

				pins_cmd {
					drive-strength = [02];
				};

				pins_dat {
					drive-strength = [02];
				};
			};

			mmc1@sdr50 {
				linux,phandle = <0x8>;
				phandle = <0x8>;

				pins_clk {
					drive-strength = [03];
				};

				pins_cmd {
					drive-strength = [02];
				};

				pins_dat {
					drive-strength = [02];
				};
			};

			mmc2@default {
				linux,phandle = <0x10>;
				phandle = <0x10>;

				pins_clk {
					drive-strength = [03];
				};

				pins_cmd {
					drive-strength = [03];
				};

				pins_dat {
					drive-strength = [03];
				};
			};

			mmc2@register_default {
				cmd_edge = [01];
				cmdrddly = [00];
				cmdrrddly = [00];
				datrddly = <0x0 0x0>;
				datwrddly = [00];
				linux,phandle = <0x11>;
				phandle = <0x11>;
				rdata_edge = [01];
				wdata_edge = [01];
			};

			mode_te_gpio {
				linux,phandle = <0x78>;
				phandle = <0x78>;

				pins_cmd_dat {
					pins = <0x2c00>;
				};
			};

			mode_te_te {
				linux,phandle = <0x79>;
				phandle = <0x79>;

				pins_cmd_dat {
					pins = <0x2c01>;
				};
			};

			msensor0@0 {
				linux,phandle = <0x76>;
				phandle = <0x76>;

				pins_cmd_dat {
					output-low;
					pins = <0x4f00>;
					slew-rate = <0x1>;
				};
			};

			msensor0@1 {
				linux,phandle = <0x77>;
				phandle = <0x77>;

				pins_cmd_dat {
					output-high;
					pins = <0x4f00>;
					slew-rate = <0x1>;
				};
			};

			pmicclkmode0 {
				linux,phandle = <0x43>;
				phandle = <0x43>;

				pins_cmd0_dat {
					pins = <0x9500>;
				};

				pins_cmd1_dat {
					bias-pull-up = <0x0>;
					pins = <0x9600>;
					slew-rate = <0x0>;
				};

				pins_cmd2_dat {
					pins = <0x9700>;
				};
			};

			pmicclkmode1 {
				linux,phandle = <0x44>;
				phandle = <0x44>;

				pins_cmd0_dat {
					pins = <0x9501>;
				};

				pins_cmd1_dat {
					pins = <0x9601>;
				};

				pins_cmd2_dat {
					pins = <0x9701>;
				};
			};

			rst@default {
				linux,phandle = <0x2e>;
				phandle = <0x2e>;
			};

			rstoutput0 {
				linux,phandle = <0x87>;
				phandle = <0x87>;

				pins_cmd_dat {
					output-low;
					pins = <0xa00>;
					slew-rate = <0x1>;
				};
			};

			rstoutput1 {
				linux,phandle = <0x88>;
				phandle = <0x88>;

				pins_cmd_dat {
					output-high;
					pins = <0xa00>;
					slew-rate = <0x1>;
				};
			};

			sd0@0 {
				linux,phandle = <0xe>;
				phandle = <0xe>;

				pins_cmd_dat {
					output-high;
					pins = <0xd00>;
					slew-rate = <0x1>;
				};
			};

			sd0@1 {
				linux,phandle = <0xf>;
				phandle = <0xf>;

				pins_cmd_dat {
					output-low;
					pins = <0xd00>;
					slew-rate = <0x1>;
				};
			};

			sleep@id1 {
				linux,phandle = <0x8a>;
				phandle = <0x8a>;

				pins_cmd_dat {
					bias-pull-down = <0x0>;
					input-enable;
					pins = <0x5100>;
					slew-rate = <0x0>;
				};
			};

			sleep@id2 {
				linux,phandle = <0x8b>;
				phandle = <0x8b>;

				pins_cmd_dat {
					bias-pull-down = <0x0>;
					input-enable;
					pins = <0x1b00>;
				};
			};

			state_eint_high {
				linux,phandle = <0x69>;
				phandle = <0x69>;

				pins_cmd_dat {
					output-high;
					pins = <0x1b00>;
					slew-rate = <0x1>;
				};
			};

			state_eint_low {
				linux,phandle = <0x6a>;
				phandle = <0x6a>;

				pins_cmd_dat {
					output-low;
					pins = <0x1b00>;
					slew-rate = <0x1>;
				};
			};

			state_irq_init {
				linux,phandle = <0x6b>;
				phandle = <0x6b>;

				pins_cmd_dat {
					bias-pull-down = <0x0>;
					pins = <0x1a00>;
					slew-rate = <0x0>;
				};
			};

			state_rst_high {
				linux,phandle = <0x67>;
				phandle = <0x67>;

				pins_cmd_dat {
					output-high;
					pins = <0x1900>;
					slew-rate = <0x1>;
				};
			};

			state_rst_low {
				linux,phandle = <0x68>;
				phandle = <0x68>;

				pins_cmd_dat {
					output-low;
					pins = <0x1900>;
					slew-rate = <0x1>;
				};
			};

			state_ven_high {
				linux,phandle = <0x65>;
				phandle = <0x65>;

				pins_cmd_dat {
					output-high;
					pins = <0x1c00>;
					slew-rate = <0x1>;
				};
			};

			state_ven_low {
				linux,phandle = <0x66>;
				phandle = <0x66>;

				pins_cmd_dat {
					output-low;
					pins = <0x1c00>;
					slew-rate = <0x1>;
				};
			};

			tp_id0_sleep {
				linux,phandle = <0x34>;
				phandle = <0x34>;

				pins_cmd_dat {
					bias-pull-down = <0x0>;
					pins = <0x1500>;
					slew-rate = <0x0>;
				};
			};

			tp_id1_sleep {
				linux,phandle = <0x35>;
				phandle = <0x35>;

				pins_cmd_dat {
					bias-pull-down = <0x0>;
					pins = <0x1300>;
					slew-rate = <0x0>;
				};
			};

			tp_id2_sleep {
				linux,phandle = <0x36>;
				phandle = <0x36>;

				pins_cmd_dat {
					bias-pull-down = <0x0>;
					pins = <0x5000>;
					slew-rate = <0x0>;
				};
			};

			tp_rst@0 {
				linux,phandle = <0x30>;
				phandle = <0x30>;

				pins_cmd_dat {
					output-low;
					pins = <0xa00>;
					slew-rate = <0x1>;
				};
			};

			tp_rst@1 {
				linux,phandle = <0x2f>;
				phandle = <0x2f>;

				pins_cmd_dat {
					output-high;
					pins = <0xa00>;
					slew-rate = <0x1>;
				};
			};

			uart0_rx_clear@gpio105 {
				linux,phandle = <0x2b>;
				phandle = <0x2b>;

				pins_cmd_dat {
					output-high;
					pins = <0x6900>;
					slew-rate = <0x1>;
				};
			};

			uart0_rx_set@gpio105 {
				linux,phandle = <0x2a>;
				phandle = <0x2a>;

				pins_cmd_dat {
					pins = <0x6901>;
				};
			};

			uart0_tx_clear@gpio106 {
				linux,phandle = <0x2d>;
				phandle = <0x2d>;

				pins_cmd_dat {
					output-high;
					pins = <0x6a00>;
					slew-rate = <0x1>;
				};
			};

			uart0_tx_set@gpio106 {
				linux,phandle = <0x2c>;
				phandle = <0x2c>;

				pins_cmd_dat {
					pins = <0x6a01>;
				};
			};

			uart0gpiodefault {
				linux,phandle = <0x29>;
				phandle = <0x29>;
			};

			vmd10default {
				linux,phandle = <0x8e>;
				phandle = <0x8e>;
			};

			vmd1@1 {
				linux,phandle = <0x8f>;
				phandle = <0x8f>;

				pins_cmd_dat {
					output-low;
					pins = <0x7300>;
					slew-rate = <0x1>;
				};
			};

			vmd1@2 {
				linux,phandle = <0x90>;
				phandle = <0x90>;

				pins_cmd_dat {
					output-high;
					pins = <0x7300>;
					slew-rate = <0x1>;
				};
			};

			vmd1_sel {
				linux,phandle = <0x1f>;
				phandle = <0x1f>;

				pins_cmd_dat {
					pins = <0x7300>;
				};
			};

			volume_down@0 {
				linux,phandle = <0x23>;
				phandle = <0x23>;

				pins_cmd_dat {
					bias-pull-up = <0x0>;
					input-enable;
					pins = <0x6800>;
					slew-rate = <0x0>;
				};
			};

			volume_up@0 {
				linux,phandle = <0x22>;
				phandle = <0x22>;

				pins_cmd_dat {
					bias-pull-up = <0x0>;
					input-enable;
					pins = <0x4d00>;
					slew-rate = <0x0>;
				};
			};
		};

		psci {
			affinity_info = <0x84000004>;
			compatible = "arm,psci";
			cpu_off = <0x84000002>;
			cpu_on = <0x84000003>;
			cpu_suspend = <0x84000001>;
			method = "smc";
		};

		ptp_fsm@1100b000 {
			clock-names = "mfg-main", "mtcmos-mfg", "therm-eem";
			clocks = <0x37 0x1 0x24 0x5 0x2 0x9>;
			compatible = "mediatek,mt6755-ptp_fsm";
			interrupts = <0x0 0x7d 0x8>;
			reg = <0x1100b000 0x1000>;
		};

		pwm@11006000 {
			clock-names = "PWM1-main", "PWM2-main", "PWM3-main", "PWM4-main", "PWM-HCLK-main", "PWM-main";
			clocks = <0x2 0xf 0x2 0x10 0x2 0x11 0x2 0x12 0x2 0xe 0x2 0x13>;
			compatible = "mediatek,pwm";
			interrupts = <0x0 0x4d 0x8>;
			reg = <0x11006000 0x1000>;
		};

		pwrap@1000d000 {
			compatible = "mediatek,pwrap";
			interrupts = <0x0 0xa3 0x4>;
			reg = <0x1000d000 0x1000>;

			mt6351 {
				compatible = "mediatek,mt6351-pmic", "mediatek,mt6353-pmic";
				debounce = <0x96 0x3e8>;
				interrupt-controller;
				interrupt-parent = <0x1c>;
				interrupts = <0x96 0x4>;
			};
		};

		rsvd@10009000 {
			compatible = "mediatek,rsvd";
			reg = <0x10009000 0x1000>;
		};

		scp_sram@10020000 {
			compatible = "mediatek,scp_sram";
			reg = <0x10020000 0x60000>;
		};

		scpsys@10001000 {
			#clock-cells = <0x1>;
			compatible = "mediatek,mt6755-scpsys";
			linux,phandle = <0x24>;
			phandle = <0x24>;
			reg = <0x10001000 0x1000 0x10006000 0x1000>;
		};

		seninf@15008000 {
			compatible = "mediatek,seninf";
			interrupts = <0x0 0xd1 0x8>;
			reg = <0x15008000 0x1000>;
		};

		sleep@10006000 {
			#address-cells = <0x1>;
			#size-cells = <0x0>;
			clock-div = <0xa>;
			clock-names = "i2c3-main";
			clocks = <0x2 0xd>;
			compatible = "mediatek,sleep";
			interrupts = <0x0 0xa5 0x8 0x0 0xa6 0x8 0x0 0xa7 0x8 0x0 0xa8 0x8 0x0 0xa9 0x8 0x0 0xaa 0x8 0x0 0xab 0x8 0x0 0xac 0x8>;
			pinctrl-0 = <0x1e>;
			pinctrl-1 = <0x1f>;
			pinctrl-names = "default", "vmd1_sel";
			reg = <0x10006000 0x1000>;
			status = "okay";

			eint_spm_vcorefs_end@153 {
				compatible = "mediatek,spm_vcorefs_end_eint";
				debounce = <0x99 0x0>;
				interrupt-parent = <0x1c>;
				interrupts = <0x99 0x4>;
			};

			eint_spm_vcorefs_start@152 {
				compatible = "mediatek,spm_vcorefs_start_eint";
				debounce = <0x98 0x0>;
				interrupt-parent = <0x1c>;
				interrupts = <0x98 0x4>;
			};
		};

		smi_common@14016000 {
			clock-names = "smi-common", "smi-larb0", "img-larb2", "vdec1-larb", "venc-venc", "venc-larb", "mtcmos-ven", "mtcmos-vde", "mtcmos-isp", "mtcmos-dis";
			clocks = <0x25 0x1 0x25 0xc 0x27 0x1 0x26 0x2 0x28 0x7 0x28 0x1 0x24 0x8 0x24 0x7 0x24 0x6 0x24 0x4>;
			compatible = "mediatek,smi_common";
			reg = <0x14016000 0x1000 0x14015000 0x1000 0x16010000 0x10000 0x15001000 0x1000 0x17001000 0x1000>;
		};

		smi_larb0@14015000 {
			compatible = "mediatek,smi_larb0";
			interrupts = <0x0 0xc9 0x8>;
			reg = <0x14015000 0x1000>;
		};

		smi_larb1@16010000 {
			compatible = "mediatek,smi_larb1";
			interrupts = <0x0 0xcf 0x8>;
			reg = <0x16010000 0x10000>;
		};

		smi_larb2@15001000 {
			compatible = "mediatek,smi_larb2";
			interrupts = <0x0 0xd0 0x8>;
			reg = <0x15001000 0x1000>;
		};

		smi_larb3@17001000 {
			compatible = "mediatek,smi_larb3";
			interrupts = <0x0 0xcb 0x8>;
			reg = <0x17001000 0x1000>;
		};

		spi@1100a000 {
			cell-index = <0x0>;
			clock-div = <0x1>;
			clock-frequency = <0x67f3540>;
			clock-names = "main";
			clocks = <0x2 0x1d>;
			compatible = "mediatek,mt6755-spi";
			interrupts = <0x0 0x76 0x8>;
			reg = <0x1100a000 0x1000>;
			spi-padmacro = <0x0>;
		};

		spi@11010000 {
			cell-index = <0x1>;
			clock-div = <0x1>;
			clock-frequency = <0x67f3540>;
			clock-names = "main";
			clocks = <0x2 0x39>;
			compatible = "mediatek,mt6755-spi";
			interrupts = <0x0 0x7a 0x8>;
			reg = <0x11010000 0x1000>;
			spi-padmacro = <0x0>;
		};

		sramrom@10202000 {
			compatible = "mediatek,sramrom";
			reg = <0x10202000 0x1000>;
		};

		sys_cirq@10204000 {
			compatible = "mediatek,mt6755-sys_cirq", "mediatek,mt6735-sys_cirq";
			interrupts = <0x0 0xf0 0x8>;
			mediatek,cirq_num = <0xa8>;
			mediatek,spi_start_offset = <0x48>;
			reg = <0x10204000 0x1000>;
		};

		syscfg_pctl_a@10002000 {
			compatible = "mediatek,mt6755-pctl-a-syscfg", "syscon";
			linux,phandle = <0x1d>;
			phandle = <0x1d>;
			reg = <0x10002000 0x1000>;
		};

		therm_ctrl@1100b000 {
			clock-names = "therm-main", "therm-auxadc";
			clocks = <0x2 0x9 0x2 0x26>;
			compatible = "mediatek,mt6755-therm_ctrl";
			interrupts = <0x0 0x4e 0x8>;
			reg = <0x1100b000 0x1000>;
		};

		topckgen@10000000 {
			#clock-cells = <0x1>;
			compatible = "mediatek,mt6755-topckgen", "mediatek,topckgen";
			linux,phandle = <0x20>;
			phandle = <0x20>;
			reg = <0x10000000 0x1000>;
		};

		topmisc@10011000 {
			compatible = "mediatek,topmisc";
			reg = <0x10011000 0x1000>;
		};

		toprgu@10007000 {
			compatible = "mediatek,toprgu";
			interrupts = <0x0 0x80 0x2>;
			reg = <0x10007000 0x1000>;
		};

		touch {
			compatible = "mediatek,mt6755-touch";
			pinctrl-0 = <0x3c>;
			pinctrl-1 = <0x84>;
			pinctrl-2 = <0x85>;
			pinctrl-3 = <0x86>;
			pinctrl-4 = <0x87>;
			pinctrl-5 = <0x88>;
			pinctrl-names = "default", "state_eint_as_int", "state_eint_output0", "state_eint_output1", "state_rst_output0", "state_rst_output1";
			status = "okay";
			tpd-filter-custom-prameters = <0x0 0x0 0x0 0x0 0x0 0x0 0x0 0x0 0x0 0x0 0x0 0x0>;
			tpd-filter-custom-speed = <0x0 0x0 0x0>;
			tpd-filter-enable = <0x1>;
			tpd-filter-pixel-density = <0x92>;
			tpd-key-dim-local = <0x5a 0x373 0x64 0x28 0xe6 0x373 0x64 0x28 0x172 0x373 0x64 0x28 0x0 0x0 0x0 0x0>;
			tpd-key-local = <0x8b 0xac 0x9e 0x0>;
			tpd-key-num = <0x3>;
			tpd-max-touch-num = <0x5>;
			tpd-resolution = <0x438 0x780>;
			use-tpd-button = <0x0>;
			vtouch-supply = <0x54>;
		};

		touch_panel {
			compatible = "mediatek, TOUCH_PANEL-eint";
			debounce = <0x1 0x0>;
			interrupt-parent = <0x1c>;
			interrupts = <0x1 0x2>;
			status = "okay";
		};

		trng@1020f000 {
			compatible = "mediatek,trng";
			interrupts = <0x0 0x8c 0x8>;
			reg = <0x1020f000 0x1000>;
		};

		usb0p@11270000 {
			compatible = "mediatek,usb0p";
			interrupts = <0x0 0x48 0x8>;
			reg = <0x11270000 0x10000>;
		};

		usb0p_sif2@11290000 {
			compatible = "mediatek,usb0p_sif2";
			reg = <0x11290000 0x10000>;
		};

		usb0p_sif@11280000 {
			compatible = "mediatek,usb0p_sif";
			reg = <0x11280000 0x10000>;
		};

		usb1p@11200000 {
			compatible = "mediatek,usb1p";
			interrupts = <0x0 0x49 0x8>;
			reg = <0x11200000 0x10000>;
		};

		usb1p_sif@11210000 {
			compatible = "mediatek,usb1p_sif";
			reg = <0x11210000 0x10000>;
		};

		usb3@11270000 {
			compatible = "mediatek,usb3";
			interrupt-names = "musb-hdrc", "xhci";
			interrupts = <0x0 0x48 0x8 0x0 0x49 0x8>;
			pinctrl-0 = <0x4b>;
			pinctrl-1 = <0x4c>;
			pinctrl-2 = <0x4d>;
			pinctrl-names = "iddig_default", "iddig_init", "iddig_output_low";
			qcom,otg_switch_gpio = <0x17>;
			reg = <0x11270000 0x10000 0x11280000 0x10000 0x11290000 0x10000>;
			reg-names = "ssusb_base", "ssusb_sif", "ssusb_sif2";
			status = "okay";
		};

		usb3_phy {
			clock-names = "sssub_clk";
			clocks = <0x2 0x34>;
			compatible = "mediatek,usb3_phy";
		};

		usb3_sif2@11290000 {
			compatible = "mediatek,usb3_sif2";
			reg = <0x11290000 0x10000>;
		};

		usb3_sif@11280000 {
			compatible = "mediatek,usb3_sif";
			reg = <0x11280000 0x10000>;
		};

		usb3_xhci@11270000 {
			compatible = "mediatek,usb3_xhci";
			interrupt-names = "xhci";
			interrupts = <0x0 0x7b 0x8>;
			pinctrl-0 = <0x4e>;
			pinctrl-1 = <0x4f>;
			pinctrl-2 = <0x50>;
			pinctrl-names = "drvvbus_default", "drvvbus_low", "drvvbus_high";
			reg = <0x11270000 0x10000 0x11280000 0x10000 0x11290000 0x10000>;
			reg-names = "ssusb_base", "ssusb_sif", "ssusb_sif2";
			status = "okay";

			eint_usb_iddig@144 {
				compatible = "mediatek,usb_iddig_bi_eint";
				debounce = <0x90 0x0>;
				interrupt-parent = <0x1c>;
				interrupts = <0x90 0x8>;
			};
		};

		usb_c_pinctrl@0 {
			compatible = "mediatek,usb_c_pinctrl";
		};

		usbphy@0 {
			compatible = "usb-nop-xceiv";
		};

		vcore_dvfs@0011cf80 {
			compatible = "mediatek,mt6755-vcorefs";
			reg = <0x11cf80 0x80>;

			eint_spm_vcorefs_end@154 {
				compatible = "mediatek,spm_vcorefs_err_eint";
				debounce = <0x9a 0x0>;
				interrupt-parent = <0x1c>;
				interrupts = <0x9a 0x4>;
			};
		};

		vdec_full_top@16020000 {
			compatible = "mediatek,mt6755-vdec_full_top";
			interrupts = <0x0 0xce 0x8>;
			reg = <0x16020000 0x10000>;
		};

		vdec_gcon@16000000 {
			#clock-cells = <0x1>;
			clock-names = "MT_CG_DISP0_SMI_COMMON", "MT_CG_VDEC0_VDEC", "MT_CG_VDEC1_LARB", "MT_CG_VENC_VENC", "MT_CG_VENC_LARB", "MT_CG_TOP_MUX_VDEC", "MT_CG_TOP_SYSPLL1_D2", "MT_CG_TOP_SYSPLL1_D4", "MT_SCP_SYS_VDE", "MT_SCP_SYS_VEN", "MT_SCP_SYS_DIS";
			clocks = <0x25 0x1 0x26 0x1 0x26 0x2 0x28 0x7 0x28 0x1 0x20 0x6 0x20 0x33 0x20 0x34 0x24 0x7 0x24 0x8 0x24 0x4>;
			compatible = "mediatek,mt6755-vdec_gcon", "mediatek,mt6755-vdecsys";
			interrupts = <0x0 0xce 0x8>;
			linux,phandle = <0x26>;
			phandle = <0x26>;
			reg = <0x16000000 0x1000>;
		};

		venc@17002000 {
			compatible = "mediatek,mt6755-venc";
			interrupts = <0x0 0xca 0x8>;
			reg = <0x17002000 0x1000>;
		};

		venc_gcon@17000000 {
			#clock-cells = <0x1>;
			compatible = "mediatek,mt6755-venc_gcon", "mediatek,mt6755-vencsys";
			interrupts = <0x0 0xca 0x8>;
			linux,phandle = <0x28>;
			phandle = <0x28>;
			reg = <0x17000000 0x1000>;
		};

		wifi@180f0000 {
			clock-names = "wifi-dma";
			clocks = <0x2 0x2a>;
			compatible = "mediatek,wifi";
			interrupts = <0x0 0xee 0x8>;
			reg = <0x180f0000 0x5c>;
		};
	};

	swtp {
		compatible = "mediatek, swtp-eint";
	};

	timer {
		clock-frequency = <0xc65d40>;
		compatible = "arm,armv8-timer";
		interrupts = <0x1 0xd 0x8 0x1 0xe 0x8 0x1 0xb 0x8 0x1 0xa 0x8>;
	};

	trusty {
		#address-cells = <0x2>;
		#size-cells = <0x2>;
		compatible = "android,trusty-smc-v1";
		ranges;

		irq {
			compatible = "android,trusty-irq-v1";
			ppi-interrupt-parent = <0x1>;
		};

		log {
			compatible = "android,trusty-log-v1";
		};

		mtee {
			compatible = "mediatek,trusty-mtee-v1";
		};

		virtio {
			compatible = "android,trusty-virtio-v1";
		};
	};

	usb_typec {
		compatible = "mediatek,fusb300-eint";
		status = "disabled";
	};

	utos {
		compatible = "microtrust,utos";
		interrupts = <0x0 0xfc 0x1 0x0 0xfd 0x1>;
	};

	vibrator@0 {
		compatible = "mediatek,vibrator";
		vib_limit = <0x0>;
		vib_timer = <0x1e>;
		vib_vol = <0x5>;
	};
};
